[part 2 of 3: package /CAN4/Cluster]
AUTOSAR XML (schema 4-3-0)
package /CAN4/Cluster  (continued)
  can cluster CAN4: baudrate=500, can-fd-baudrate=2000  (continued)
    can physical channel CAN4: comm-connectors=ConnCAN4  (continued)
      frame CAN4_ZONE_DR_VCU: id 0x1F1, frame-length=48, can-addressing-mode=STANDARD, can-fd-frame-support=true, can-frame-rx-behavior=CAN-FD, can-frame-tx-behavior=CAN-FD
        pdu CAN4_ZONE_DR_VCU: length=48, minimum-delay=0.0, transmission-mode-true-timing={cyclic-timing=time-period=0.02, event-controlled-timing={number-of-repetitions=0, repetition-period=0}}, unused-bit-pattern=0
          mapping CAN4_SG_ZONE_DR_VCU: i-signal-group=CAN4_SG_ZONE_DR_VCU, start-position=0, transfer-property=TRIGGERED-ON-CHANGE
          signal CAN4_APTC_Err: start 215, 2 bit, big-endian, i-signal-type=PRIMITIVE, init-value=constant-reference=Init_CAN4_APTC_Err, base-type=uint8, implementation-data-type=uint8, transfer-property=TRIGGERED-ON-CHANGE
          signal CAN4_Blower_Err: start 213, 2 bit, big-endian, i-signal-type=PRIMITIVE, init-value=constant-reference=Init_CAN4_Blower_Err, base-type=uint8, implementation-data-type=uint8, transfer-property=TRIGGERED-ON-CHANGE
          signal CAN4_Blower_FB: start 71, 4 bit, big-endian, i-signal-type=PRIMITIVE, init-value=constant-reference=Init_CAN4_Blower_FB, base-type=uint8, implementation-data-type=uint8, transfer-property=PENDING
          signal CAN4_DrADASCurr: start 23, 8 bit, big-endian, i-signal-type=PRIMITIVE, init-value=constant-reference=Init_CAN4_DrADASCurr, base-type=uint8, implementation-data-type=uint8, transfer-property=PENDING
          signal CAN4_DrAPWLINErr: start 254, 1 bit, big-endian, i-signal-type=PRIMITIVE, init-value=constant-reference=Init_CAN4_DrAPWLINErr, base-type=uint8, implementation-data-type=uint8, transfer-property=TRIGGERED-ON-CHANGE
          signal CAN4_DrAPWStaErr: start 4, 1 bit, big-endian, i-signal-type=PRIMITIVE, init-value=constant-reference=Init_CAN4_DrAPWStaErr, base-type=uint8, implementation-data-type=uint8, transfer-property=TRIGGERED-ON-CHANGE
          signal CAN4_DrAuBoxPwrN1Curr: start 39, 8 bit, big-endian, i-signal-type=PRIMITIVE, init-value=constant-reference=Init_CAN4_DrAuBoxPwrN1Curr, base-type=uint8, implementation-data-type=uint8, transfer-property=PENDING
          signal CAN4_DrAuBoxPwrN2Curr: start 31, 8 bit, big-endian, i-signal-type=PRIMITIVE, init-value=constant-reference=Init_CAN4_DrAuBoxPwrN2Curr, base-type=uint8, implementation-data-type=uint8, transfer-property=PENDING
          signal CAN4_DrColumnSWFault: start 9, 2 bit, big-endian, i-signal-type=PRIMITIVE, init-value=constant-reference=Init_CAN4_DrColumnSWFault, base-type=uint8, implementation-data-type=uint8, transfer-property=PENDING
          signal CAN4_DrCtrlBDVolt: start 67, 12 bit, big-endian, i-signal-type=PRIMITIVE, init-value=constant-reference=Init_CAN4_DrCtrlBDVolt, base-type=uint16, implementation-data-type=uint16, transfer-property=PENDING
          signal CAN4_DrCtrlTemp: start 87, 16 bit, big-endian, i-signal-type=PRIMITIVE, init-value=constant-reference=Init_CAN4_DrCtrlTemp, base-type=uint16, implementation-data-type=uint16, transfer-property=PENDING
          signal CAN4_DrEOBDFault: start 1, 2 bit, big-endian, i-signal-type=PRIMITIVE, init-value=constant-reference=Init_CAN4_DrEOBDFault, base-type=uint8, implementation-data-type=uint8, transfer-property=PENDING
          signal CAN4_DrIVIFault: start 3, 2 bit, big-endian, i-signal-type=PRIMITIVE, init-value=constant-reference=Init_CAN4_DrIVIFault, base-type=uint8, implementation-data-type=uint8, transfer-property=PENDING
          signal CAN4_DrInfoErrSta: start 253, 1 bit, big-endian, i-signal-type=PRIMITIVE, init-value=constant-reference=Init_CAN4_DrInfoErrSta, base-type=uint8, implementation-data-type=uint8, transfer-property=TRIGGERED-ON-CHANGE
          signal CAN4_DrInfoFault: start 15, 2 bit, big-endian, i-signal-type=PRIMITIVE, init-value=constant-reference=Init_CAN4_DrInfoFault, base-type=uint8, implementation-data-type=uint8, transfer-property=PENDING
          signal CAN4_DrONA1ErrSta: start 252, 1 bit, big-endian, i-signal-type=PRIMITIVE, init-value=constant-reference=Init_CAN4_DrONA1ErrSta, base-type=uint8, implementation-data-type=uint8, transfer-property=TRIGGERED-ON-CHANGE
          signal CAN4_DrPMMLVOutPErrLmp: start 6, 1 bit, big-endian, i-signal-type=PRIMITIVE, init-value=constant-reference=Init_CAN4_DrPMMLVOutPErrLmp, base-type=uint8, implementation-data-type=uint8, transfer-property=TRIGGERED-ON-CHANGE
          signal CAN4_DrPMMLimpHomeActReq: start 5, 1 bit, big-endian, i-signal-type=PRIMITIVE, init-value=constant-reference=Init_CAN4_DrPMMLimpHomeActReq, base-type=uint8, implementation-data-type=uint8, transfer-property=TRIGGERED-ON-CHANGE
          signal CAN4_DrPMMSysErrLmp: start 7, 1 bit, big-endian, i-signal-type=PRIMITIVE, init-value=constant-reference=Init_CAN4_DrPMMSysErrLmp, base-type=uint8, implementation-data-type=uint8, transfer-property=TRIGGERED-ON-CHANGE
          signal CAN4_DrPowerTemp1: start 103, 16 bit, big-endian, i-signal-type=PRIMITIVE, init-value=constant-reference=Init_CAN4_DrPowerTemp1, base-type=uint16, implementation-data-type=uint16, transfer-property=PENDING
          signal CAN4_DrPowerTemp2: start 119, 16 bit, big-endian, i-signal-type=PRIMITIVE, init-value=constant-reference=Init_CAN4_DrPowerTemp2, base-type=uint16, implementation-data-type=uint16, transfer-property=PENDING
          signal CAN4_DrPwrInformationSta: start 261, 1 bit, big-endian, i-signal-type=PRIMITIVE, init-value=constant-reference=Init_CAN4_DrPwrInformationSta, base-type=uint8, implementation-data-type=uint8, transfer-property=TRIGGERED-ON-CHANGE
          signal CAN4_DrPwrONA1Curr: start 63, 8 bit, big-endian, i-signal-type=PRIMITIVE, init-value=constant-reference=Init_CAN4_DrPwrONA1Curr, base-type=uint8, implementation-data-type=uint8, transfer-property=PENDING
          signal CAN4_DrPwrONA2Curr: start 55, 8 bit, big-endian, i-signal-type=PRIMITIVE, init-value=constant-reference=Init_CAN4_DrPwrONA2Curr, base-type=uint8, implementation-data-type=uint8, transfer-property=PENDING
          signal CAN4_DrPwrSta: start 258, 3 bit, big-endian, i-signal-type=PRIMITIVE, init-value=constant-reference=Init_CAN4_DrPwrSta, base-type=uint8, implementation-data-type=uint8, transfer-property=TRIGGERED-ON-CHANGE
          signal CAN4_DrPwrStdbyACurr: start 47, 8 bit, big-endian, i-signal-type=PRIMITIVE, init-value=constant-reference=Init_CAN4_DrPwrStdbyACurr, base-type=uint8, implementation-data-type=uint8, transfer-property=PENDING
          signal CAN4_DrPwrWinErrSta: start 255, 1 bit, big-endian, i-signal-type=PRIMITIVE, init-value=constant-reference=Init_CAN4_DrPwrWinErrSta, base-type=uint8, implementation-data-type=uint8, transfer-property=TRIGGERED-ON-CHANGE
          signal CAN4_DrPwrWindowECUFault: start 13, 2 bit, big-endian, i-signal-type=PRIMITIVE, init-value=constant-reference=Init_CAN4_DrPwrWindowECUFault, base-type=uint8, implementation-data-type=uint8, transfer-property=PENDING
          signal CAN4_DrSCPSysErrLmp: start 260, 1 bit, big-endian, i-signal-type=PRIMITIVE, init-value=constant-reference=Init_CAN4_DrSCPSysErrLmp, base-type=uint8, implementation-data-type=uint8, transfer-property=TRIGGERED-ON-CHANGE
          signal CAN4_DrStdAErrSta: start 251, 1 bit, big-endian, i-signal-type=PRIMITIVE, init-value=constant-reference=Init_CAN4_DrStdAErrSta, base-type=uint8, implementation-data-type=uint8, transfer-property=TRIGGERED-ON-CHANGE
          signal CAN4_DrTHCMFault: start 11, 2 bit, big-endian, i-signal-type=PRIMITIVE, init-value=constant-reference=Init_CAN4_DrTHCMFault, base-type=uint8, implementation-data-type=uint8, transfer-property=PENDING
          signal CAN4_RegenSW_Err: start 262, 1 bit, big-endian, i-signal-type=PRIMITIVE, init-value=constant-reference=Init_CAN4_RegenSW_Err, base-type=uint8, implementation-data-type=uint8, transfer-property=TRIGGERED-ON-CHANGE
          signal CAN4_SolarL: start 207, 8 bit, big-endian, i-signal-type=PRIMITIVE, init-value=constant-reference=Init_CAN4_SolarL, base-type=uint8, implementation-data-type=uint8, transfer-property=PENDING
          signal CAN4_SolarL_Err: start 225, 2 bit, big-endian, i-signal-type=PRIMITIVE, init-value=constant-reference=Init_CAN4_SolarL_Err, base-type=uint8, implementation-data-type=uint8, transfer-property=TRIGGERED-ON-CHANGE
          signal CAN4_SolarR: start 199, 8 bit, big-endian, i-signal-type=PRIMITIVE, init-value=constant-reference=Init_CAN4_SolarR, base-type=uint8, implementation-data-type=uint8, transfer-property=PENDING
          signal CAN4_SolarR_Err: start 227, 2 bit, big-endian, i-signal-type=PRIMITIVE, init-value=constant-reference=Init_CAN4_SolarR_Err, base-type=uint8, implementation-data-type=uint8, transfer-property=TRIGGERED-ON-CHANGE
          signal CAN4_T_Face_L: start 175, 8 bit, big-endian, i-signal-type=PRIMITIVE, init-value=constant-reference=Init_CAN4_T_Face_L, base-type=uint8, implementation-data-type=uint8, transfer-property=PENDING
          signal CAN4_T_Face_L_Err: start 217, 2 bit, big-endian, i-signal-type=PRIMITIVE, init-value=constant-reference=Init_CAN4_T_Face_L_Err, base-type=uint8, implementation-data-type=uint8, transfer-property=TRIGGERED-ON-CHANGE
          signal CAN4_T_Face_R: start 167, 8 bit, big-endian, i-signal-type=PRIMITIVE, init-value=constant-reference=Init_CAN4_T_Face_R, base-type=uint8, implementation-data-type=uint8, transfer-property=PENDING
          signal CAN4_T_Face_R_Err: start 221, 2 bit, big-endian, i-signal-type=PRIMITIVE, init-value=constant-reference=Init_CAN4_T_Face_R_Err, base-type=uint8, implementation-data-type=uint8, transfer-property=TRIGGERED-ON-CHANGE
          signal CAN4_T_Face_Rr: start 151, 8 bit, big-endian, i-signal-type=PRIMITIVE, init-value=constant-reference=Init_CAN4_T_Face_Rr, base-type=uint8, implementation-data-type=uint8, transfer-property=PENDING
          signal CAN4_T_Face_Rr_Err: start 209, 2 bit, big-endian, i-signal-type=PRIMITIVE, init-value=constant-reference=Init_CAN4_T_Face_Rr_Err, base-type=uint8, implementation-data-type=uint8, transfer-property=TRIGGERED-ON-CHANGE
          signal CAN4_T_Foot_L: start 159, 8 bit, big-endian, i-signal-type=PRIMITIVE, init-value=constant-reference=Init_CAN4_T_Foot_L, base-type=uint8, implementation-data-type=uint8, transfer-property=PENDING
          signal CAN4_T_Foot_L_Err: start 219, 2 bit, big-endian, i-signal-type=PRIMITIVE, init-value=constant-reference=Init_CAN4_T_Foot_L_Err, base-type=uint8, implementation-data-type=uint8, transfer-property=TRIGGERED-ON-CHANGE
          signal CAN4_T_Foot_R: start 135, 8 bit, big-endian, i-signal-type=PRIMITIVE, init-value=constant-reference=Init_CAN4_T_Foot_R, base-type=uint8, implementation-data-type=uint8, transfer-property=PENDING
          signal CAN4_T_Foot_R_Err: start 223, 2 bit, big-endian, i-signal-type=PRIMITIVE, init-value=constant-reference=Init_CAN4_T_Foot_R_Err, base-type=uint8, implementation-data-type=uint8, transfer-property=TRIGGERED-ON-CHANGE
          signal CAN4_T_Foot_Rr: start 143, 8 bit, big-endian, i-signal-type=PRIMITIVE, init-value=constant-reference=Init_CAN4_T_Foot_Rr, base-type=uint8, implementation-data-type=uint8, transfer-property=PENDING
          signal CAN4_T_Foot_Rr_Err: start 211, 2 bit, big-endian, i-signal-type=PRIMITIVE, init-value=constant-reference=Init_CAN4_T_Foot_Rr_Err, base-type=uint8, implementation-data-type=uint8, transfer-property=TRIGGERED-ON-CHANGE
          signal CAN4_Tevap: start 183, 8 bit, big-endian, i-signal-type=PRIMITIVE, init-value=constant-reference=Init_CAN4_Tevap, base-type=uint8, implementation-data-type=uint8, transfer-property=PENDING
          signal CAN4_Tevap_Err: start 229, 2 bit, big-endian, i-signal-type=PRIMITIVE, init-value=constant-reference=Init_CAN4_Tevap_Err, base-type=uint8, implementation-data-type=uint8, transfer-property=TRIGGERED-ON-CHANGE
          signal CAN4_Tincar: start 191, 8 bit, big-endian, i-signal-type=PRIMITIVE, init-value=constant-reference=Init_CAN4_Tincar, base-type=uint8, implementation-data-type=uint8, transfer-property=PENDING
          signal CAN4_Tincar_Err: start 231, 2 bit, big-endian, i-signal-type=PRIMITIVE, init-value=constant-reference=Init_CAN4_Tincar_Err, base-type=uint8, implementation-data-type=uint8, transfer-property=TRIGGERED-ON-CHANGE
          signal CAN4_ZDR_SYS_APMRetryCnt_Sta: start 247, 8 bit, big-endian, i-signal-type=PRIMITIVE, init-value=constant-reference=Init_CAN4_ZDR_SYS_APMRetryCnt_Sta, base-type=uint8, implementation-data-type=uint8, transfer-property=TRIGGERED-ON-CHANGE
          signal CAN4_ZDR_SYS_BSWSleepReq_Sta: start 259, 1 bit, big-endian, i-signal-type=PRIMITIVE, init-value=constant-reference=Init_CAN4_ZDR_SYS_BSWSleepReq_Sta, base-type=uint8, implementation-data-type=uint8, transfer-property=TRIGGERED-ON-CHANGE
          signal CAN4_ZDR_SYS_CSWRetryCnt_Sta: start 239, 8 bit, big-endian, i-signal-type=PRIMITIVE, init-value=constant-reference=Init_CAN4_ZDR_SYS_CSWRetryCnt_Sta, base-type=uint8, implementation-data-type=uint8, transfer-property=TRIGGERED-ON-CHANGE
          signal CAN4_ZDR_VCU_HWReset_Sta: start 268, 5 bit, big-endian, i-signal-type=PRIMITIVE, init-value=constant-reference=Init_CAN4_ZDR_VCU_HWReset_Sta, base-type=uint8, implementation-data-type=uint8, transfer-property=TRIGGERED-ON-CHANGE
          signal CAN4_ZDR_VCU_PwrSupply_Sta: start 263, 1 bit, big-endian, i-signal-type=PRIMITIVE, init-value=constant-reference=Init_CAN4_ZDR_VCU_PwrSupply_Sta, base-type=uint8, implementation-data-type=uint8, transfer-property=TRIGGERED-ON-CHANGE
          signal CAN4_ZoneDrMalfunLevel: start 250, 3 bit, big-endian, i-signal-type=PRIMITIVE, init-value=constant-reference=Init_CAN4_ZoneDrMalfunLevel, base-type=uint8, implementation-data-type=uint8, transfer-property=TRIGGERED-ON-CHANGE
      frame CAN4_ZONE_FR1: id 0x31C, frame-length=64, can-addressing-mode=STANDARD, can-fd-frame-support=true, can-frame-rx-behavior=CAN-FD, can-frame-tx-behavior=CAN-FD
        pdu CAN4_ZONE_FR1: length=64, minimum-delay=0.0, transmission-mode-true-timing={cyclic-timing=time-period=0.1, event-controlled-timing={number-of-repetitions=0, repetition-period=0}}, unused-bit-pattern=0
          mapping CAN4_SG_ZONE_FR1: i-signal-group=CAN4_SG_ZONE_FR1, start-position=0, transfer-property=TRIGGERED-ON-CHANGE
          signal CAN4_AGS_Calibration_Enabled: start 191, 1 bit, big-endian, i-signal-type=PRIMITIVE, init-value=constant-reference=Init_CAN4_AGS_Calibration_Enabled, base-type=uint8, implementation-data-type=uint8, transfer-property=PENDING
          signal CAN4_AGS_Position_Request: start 183, 8 bit, big-endian, i-signal-type=PRIMITIVE, init-value=constant-reference=Init_CAN4_AGS_Position_Request, base-type=uint8, implementation-data-type=uint8, transfer-property=PENDING
          signal CAN4_BDC_1_MoveEnable: start 173, 1 bit, big-endian, i-signal-type=PRIMITIVE, init-value=constant-reference=Init_CAN4_BDC_1_MoveEnable, base-type=uint8, implementation-data-type=uint8, transfer-property=PENDING
          signal CAN4_BDC_1_ReqMovePos: start 143, 8 bit, big-endian, i-signal-type=PRIMITIVE, init-value=constant-reference=Init_CAN4_BDC_1_ReqMovePos, base-type=uint8, implementation-data-type=uint8, transfer-property=PENDING
          signal CAN4_BMSChksmHSC6: start 47, 8 bit, big-endian, i-signal-type=PRIMITIVE, init-value=constant-reference=Init_CAN4_BMSChksmHSC6, base-type=uint8, implementation-data-type=uint8, transfer-property=PENDING
          signal CAN4_BMSEnbPTCHSC6: start 69, 1 bit, big-endian, i-signal-type=PRIMITIVE, init-value=constant-reference=Init_CAN4_BMSEnbPTCHSC6, base-type=uint8, implementation-data-type=uint8, transfer-property=PENDING
          signal CAN4_BMSInptClntTemHSC6: start 24, 9 bit, big-endian, i-signal-type=PRIMITIVE, init-value=constant-reference=Init_CAN4_BMSInptClntTemHSC6, base-type=uint16, implementation-data-type=uint16, transfer-property=PENDING
          signal CAN4_BMSPackVol_h6HSC6: start 67, 12 bit, big-endian, i-signal-type=PRIMITIVE, init-value=constant-reference=Init_CAN4_BMSPackVol_h6HSC6, base-type=uint16, implementation-data-type=uint16, transfer-property=PENDING
          signal CAN4_BMSReqMdHSC6: start 71, 2 bit, big-endian, i-signal-type=PRIMITIVE, init-value=constant-reference=Init_CAN4_BMSReqMdHSC6, base-type=uint8, implementation-data-type=uint8, transfer-property=PENDING
          signal CAN4_BMSReqPWMHSC6: start 31, 7 bit, big-endian, i-signal-type=PRIMITIVE, init-value=constant-reference=Init_CAN4_BMSReqPWMHSC6, base-type=uint8, implementation-data-type=uint8, transfer-property=PENDING
          signal CAN4_BMSReqPwrHSC6: start 15, 16 bit, big-endian, i-signal-type=PRIMITIVE, init-value=constant-reference=Init_CAN4_BMSReqPwrHSC6, base-type=uint16, implementation-data-type=uint16, transfer-property=PENDING
          signal CAN4_BMSReqRlngCtrHSC6: start 7, 4 bit, big-endian, i-signal-type=PRIMITIVE, init-value=constant-reference=Init_CAN4_BMSReqRlngCtrHSC6, base-type=uint8, implementation-data-type=uint8, transfer-property=PENDING
          signal CAN4_BMSReqTapPosHSC6: start 3, 4 bit, big-endian, i-signal-type=PRIMITIVE, init-value=constant-reference=Init_CAN4_BMSReqTapPosHSC6, base-type=uint8, implementation-data-type=uint8, transfer-property=PENDING
          signal CAN4_CCM_SpdCmd: start 54, 15 bit, big-endian, i-signal-type=PRIMITIVE, init-value=constant-reference=Init_CAN4_CCM_SpdCmd, base-type=uint16, implementation-data-type=uint16, transfer-property=PENDING
          signal CAN4_CCV4_MoveEnable: start 168, 1 bit, big-endian, i-signal-type=PRIMITIVE, init-value=constant-reference=Init_CAN4_CCV4_MoveEnable, base-type=uint8, implementation-data-type=uint8, transfer-property=PENDING
          signal CAN4_CCV4_ReqMovePos: start 169, 1 bit, big-endian, i-signal-type=PRIMITIVE, init-value=constant-reference=Init_CAN4_CCV4_ReqMovePos, base-type=uint8, implementation-data-type=uint8, transfer-property=PENDING
          signal CAN4_ChargeInletLockSta: start 55, 1 bit, big-endian, i-signal-type=PRIMITIVE, init-value=constant-reference=Init_CAN4_ChargeInletLockSta, base-type=uint8, implementation-data-type=uint8, transfer-property=TRIGGERED-ON-CHANGE
          signal CAN4_CompProEN: start 68, 1 bit, big-endian, i-signal-type=PRIMITIVE, init-value=constant-reference=Init_CAN4_CompProEN, base-type=uint8, implementation-data-type=uint8, transfer-property=PENDING
          signal CAN4_EWP1_Default_Operation_EWP_Rq: start 170, 1 bit, big-endian, i-signal-type=PRIMITIVE, init-value=constant-reference=Init_CAN4_EWP1_Default_Operation_EWP_Rq, base-type=uint8, implementation-data-type=uint8, transfer-property=PENDING
          signal CAN4_EWP1_RPM_Target_EWP_Rq: start 119, 8 bit, big-endian, i-signal-type=PRIMITIVE, init-value=constant-reference=Init_CAN4_EWP1_RPM_Target_EWP_Rq, base-type=uint8, implementation-data-type=uint8, transfer-property=PENDING
          signal CAN4_EWP2_Default_Operation_EWP_Rq: start 171, 1 bit, big-endian, i-signal-type=PRIMITIVE, init-value=constant-reference=Init_CAN4_EWP2_Default_Operation_EWP_Rq, base-type=uint8, implementation-data-type=uint8, transfer-property=PENDING
          signal CAN4_EWP2_RPM_Target_EWP_Rq: start 127, 8 bit, big-endian, i-signal-type=PRIMITIVE, init-value=constant-reference=Init_CAN4_EWP2_RPM_Target_EWP_Rq, base-type=uint8, implementation-data-type=uint8, transfer-property=PENDING
          signal CAN4_EWP3_Default_Operation_EWP_Rq: start 172, 1 bit, big-endian, i-signal-type=PRIMITIVE, init-value=constant-reference=Init_CAN4_EWP3_Default_Operation_EWP_Rq, base-type=uint8, implementation-data-type=uint8, transfer-property=PENDING
          signal CAN4_EWP3_RPM_Target_EWP_Rq: start 135, 8 bit, big-endian, i-signal-type=PRIMITIVE, init-value=constant-reference=Init_CAN4_EWP3_RPM_Target_EWP_Rq, base-type=uint8, implementation-data-type=uint8, transfer-property=PENDING
          signal CAN4_EXV2_Cmd_Init_Rq: start 162, 3 bit, big-endian, i-signal-type=PRIMITIVE, init-value=constant-reference=Init_CAN4_EXV2_Cmd_Init_Rq, base-type=uint8, implementation-data-type=uint8, transfer-property=PENDING
          signal CAN4_EXV2_Cmd_Move_Enbl: start 167, 1 bit, big-endian, i-signal-type=PRIMITIVE, init-value=constant-reference=Init_CAN4_EXV2_Cmd_Move_Enbl, base-type=uint8, implementation-data-type=uint8, transfer-property=PENDING
          signal CAN4_EXV2_Cmd_Set_Rq: start 103, 16 bit, big-endian, i-signal-type=PRIMITIVE, init-value=constant-reference=Init_CAN4_EXV2_Cmd_Set_Rq, base-type=uint16, implementation-data-type=uint16, transfer-property=PENDING
          signal CAN4_EXV_Cmd_Init_Rq: start 165, 3 bit, big-endian, i-signal-type=PRIMITIVE, init-value=constant-reference=Init_CAN4_EXV_Cmd_Init_Rq, base-type=uint8, implementation-data-type=uint8, transfer-property=PENDING
          signal CAN4_EXV_Cmd_Move_Enbl: start 166, 1 bit, big-endian, i-signal-type=PRIMITIVE, init-value=constant-reference=Init_CAN4_EXV_Cmd_Move_Enbl, base-type=uint8, implementation-data-type=uint8, transfer-property=PENDING
          signal CAN4_EXV_Cmd_Set_Rq: start 87, 16 bit, big-endian, i-signal-type=PRIMITIVE, init-value=constant-reference=Init_CAN4_EXV_Cmd_Set_Rq, base-type=uint16, implementation-data-type=uint16, transfer-property=PENDING
          signal CAN4_FLPosLPErr: start 197, 1 bit, big-endian, i-signal-type=PRIMITIVE, init-value=constant-reference=Init_CAN4_FLPosLPErr, base-type=uint8, implementation-data-type=uint8, transfer-property=TRIGGERED-ON-CHANGE
          signal CAN4_FLTurnLPErr: start 198, 1 bit, big-endian, i-signal-type=PRIMITIVE, init-value=constant-reference=Init_CAN4_FLTurnLPErr, base-type=uint8, implementation-data-type=uint8, transfer-property=TRIGGERED-ON-CHANGE
          signal CAN4_FLTurnLampC: start 159, 8 bit, big-endian, i-signal-type=PRIMITIVE, init-value=constant-reference=Init_CAN4_FLTurnLampC, base-type=uint8, implementation-data-type=uint8, transfer-property=TRIGGERED-ON-CHANGE
          signal CAN4_FLTurn_Light_Warning: start 203, 1 bit, big-endian, i-signal-type=PRIMITIVE, init-value=constant-reference=Init_CAN4_FLTurn_Light_Warning, base-type=uint8, implementation-data-type=uint8, transfer-property=PENDING
          signal CAN4_FRPosLPErr: start 213, 1 bit, big-endian, i-signal-type=PRIMITIVE, init-value=constant-reference=Init_CAN4_FRPosLPErr, base-type=uint8, implementation-data-type=uint8, transfer-property=TRIGGERED-ON-CHANGE
          signal CAN4_FRTurnLPErr: start 214, 1 bit, big-endian, i-signal-type=PRIMITIVE, init-value=constant-reference=Init_CAN4_FRTurnLPErr, base-type=uint8, implementation-data-type=uint8, transfer-property=TRIGGERED-ON-CHANGE
          signal CAN4_FRTurnLampC: start 151, 8 bit, big-endian, i-signal-type=PRIMITIVE, init-value=constant-reference=Init_CAN4_FRTurnLampC, base-type=uint8, implementation-data-type=uint8, transfer-property=TRIGGERED-ON-CHANGE
          signal CAN4_FRTurn_Light_Warning: start 219, 1 bit, big-endian, i-signal-type=PRIMITIVE, init-value=constant-reference=Init_CAN4_FRTurn_Light_Warning, base-type=uint8, implementation-data-type=uint8, transfer-property=PENDING
          signal CAN4_FWiperAS: start 175, 1 bit, big-endian, i-signal-type=PRIMITIVE, init-value=constant-reference=Init_CAN4_FWiperAS, base-type=uint8, implementation-data-type=uint8, transfer-property=TRIGGERED-ON-CHANGE
          signal CAN4_FWiperProtection: start 174, 1 bit, big-endian, i-signal-type=PRIMITIVE, init-value=constant-reference=Init_CAN4_FWiperProtection, base-type=uint8, implementation-data-type=uint8, transfer-property=TRIGGERED-ON-CHANGE
          signal CAN4_LADBErr: start 194, 1 bit, big-endian, i-signal-type=PRIMITIVE, init-value=constant-reference=Init_CAN4_LADBErr, base-type=uint8, implementation-data-type=uint8, transfer-property=TRIGGERED-ON-CHANGE
          signal CAN4_LADB_Hibeam_Indication: start 192, 1 bit, big-endian, i-signal-type=PRIMITIVE, init-value=constant-reference=Init_CAN4_LADB_Hibeam_Indication, base-type=uint8, implementation-data-type=uint8, transfer-property=PENDING
          signal CAN4_LADB_Operation_Status: start 207, 1 bit, big-endian, i-signal-type=PRIMITIVE, init-value=constant-reference=Init_CAN4_LADB_Operation_Status, base-type=uint8, implementation-data-type=uint8, transfer-property=PENDING
          signal CAN4_LADB_Warning: start 206, 1 bit, big-endian, i-signal-type=PRIMITIVE, init-value=constant-reference=Init_CAN4_LADB_Warning, base-type=uint8, implementation-data-type=uint8, transfer-property=PENDING
          signal CAN4_LAHB_Warning: start 204, 1 bit, big-endian, i-signal-type=PRIMITIVE, init-value=constant-reference=Init_CAN4_LAHB_Warning, base-type=uint8, implementation-data-type=uint8, transfer-property=PENDING
          signal CAN4_LDRLErr: start 193, 1 bit, big-endian, i-signal-type=PRIMITIVE, init-value=constant-reference=Init_CAN4_LDRLErr, base-type=uint8, implementation-data-type=uint8, transfer-property=TRIGGERED-ON-CHANGE
          signal CAN4_LDRL_Warning: start 202, 1 bit, big-endian, i-signal-type=PRIMITIVE, init-value=constant-reference=Init_CAN4_LDRL_Warning, base-type=uint8, implementation-data-type=uint8, transfer-property=PENDING
          signal CAN4_LH_BeamErr: start 195, 1 bit, big-endian, i-signal-type=PRIMITIVE, init-value=constant-reference=Init_CAN4_LH_BeamErr, base-type=uint8, implementation-data-type=uint8, transfer-property=TRIGGERED-ON-CHANGE
          signal CAN4_LLB_Warning: start 205, 1 bit, big-endian, i-signal-type=PRIMITIVE, init-value=constant-reference=Init_CAN4_LLB_Warning, base-type=uint8, implementation-data-type=uint8, transfer-property=PENDING
          signal CAN4_LL_BeamErr: start 196, 1 bit, big-endian, i-signal-type=PRIMITIVE, init-value=constant-reference=Init_CAN4_LL_BeamErr, base-type=uint8, implementation-data-type=uint8, transfer-property=TRIGGERED-ON-CHANGE
          signal CAN4_Lposition_Lamp_Warning: start 199, 1 bit, big-endian, i-signal-type=PRIMITIVE, init-value=constant-reference=Init_CAN4_Lposition_Lamp_Warning, base-type=uint8, implementation-data-type=uint8, transfer-property=PENDING
          signal CAN4_RADBErr: start 210, 1 bit, big-endian, i-signal-type=PRIMITIVE, init-value=constant-reference=Init_CAN4_RADBErr, base-type=uint8, implementation-data-type=uint8, transfer-property=TRIGGERED-ON-CHANGE
          signal CAN4_RADB_Hibeam_Indication: start 208, 1 bit, big-endian, i-signal-type=PRIMITIVE, init-value=constant-reference=Init_CAN4_RADB_Hibeam_Indication, base-type=uint8, implementation-data-type=uint8, transfer-property=PENDING
          signal CAN4_RADB_Operation_Status: start 223, 1 bit, big-endian, i-signal-type=PRIMITIVE, init-value=constant-reference=Init_CAN4_RADB_Operation_Status, base-type=uint8, implementation-data-type=uint8, transfer-property=PENDING
          signal CAN4_RADB_Warning: start 222, 1 bit, big-endian, i-signal-type=PRIMITIVE, init-value=constant-reference=Init_CAN4_RADB_Warning, base-type=uint8, implementation-data-type=uint8, transfer-property=PENDING
          signal CAN4_RAHB_Warning: start 220, 1 bit, big-endian, i-signal-type=PRIMITIVE, init-value=constant-reference=Init_CAN4_RAHB_Warning, base-type=uint8, implementation-data-type=uint8, transfer-property=PENDING
          signal CAN4_RDRLErr: start 209, 1 bit, big-endian, i-signal-type=PRIMITIVE, init-value=constant-reference=Init_CAN4_RDRLErr, base-type=uint8, implementation-data-type=uint8, transfer-property=TRIGGERED-ON-CHANGE
          signal CAN4_RDRL_Warning: start 218, 1 bit, big-endian, i-signal-type=PRIMITIVE, init-value=constant-reference=Init_CAN4_RDRL_Warning, base-type=uint8, implementation-data-type=uint8, transfer-property=PENDING
          signal CAN4_RH_BeamErr: start 211, 1 bit, big-endian, i-signal-type=PRIMITIVE, init-value=constant-reference=Init_CAN4_RH_BeamErr, base-type=uint8, implementation-data-type=uint8, transfer-property=TRIGGERED-ON-CHANGE
          signal CAN4_RLB_Warning: start 221, 1 bit, big-endian, i-signal-type=PRIMITIVE, init-value=constant-reference=Init_CAN4_RLB_Warning, base-type=uint8, implementation-data-type=uint8, transfer-property=PENDING
          signal CAN4_RL_BeamErr: start 212, 1 bit, big-endian, i-signal-type=PRIMITIVE, init-value=constant-reference=Init_CAN4_RL_BeamErr, base-type=uint8, implementation-data-type=uint8, transfer-property=TRIGGERED-ON-CHANGE
          signal CAN4_Rposition_Lamp_Warning: start 215, 1 bit, big-endian, i-signal-type=PRIMITIVE, init-value=constant-reference=Init_CAN4_Rposition_Lamp_Warning, base-type=uint8, implementation-data-type=uint8, transfer-property=PENDING
          signal CAN4_TrailerCheck: start 190, 1 bit, big-endian, i-signal-type=PRIMITIVE, init-value=constant-reference=Init_CAN4_TrailerCheck, base-type=uint8, implementation-data-type=uint8, transfer-property=TRIGGERED-ON-CHANGE
          signal CAN4_TrailerModeSta: start 189, 2 bit, big-endian, i-signal-type=PRIMITIVE, init-value=constant-reference=Init_CAN4_TrailerModeSta, base-type=uint8, implementation-data-type=uint8, transfer-property=TRIGGERED-ON-CHANGE
          signal CAN4_ZFR_BCM_ChargerDoorSW_Sta: start 187, 1 bit, big-endian, i-signal-type=PRIMITIVE, init-value=constant-reference=Init_CAN4_ZFR_BCM_ChargerDoorSW_Sta, base-type=uint8, implementation-data-type=uint8, transfer-property=TRIGGERED-ON-CHANGE
          signal CAN4_ZFR_THCM_CLEVentActY_Sta: start 262, 7 bit, big-endian, i-signal-type=PRIMITIVE, init-value=constant-reference=Init_CAN4_ZFR_THCM_CLEVentActY_Sta, base-type=uint8, implementation-data-type=uint8, transfer-property=PENDING
          signal CAN4_ZFR_THCM_CLEVentActZ_Sta: start 270, 7 bit, big-endian, i-signal-type=PRIMITIVE, init-value=constant-reference=Init_CAN4_ZFR_THCM_CLEVentActZ_Sta, base-type=uint8, implementation-data-type=uint8, transfer-property=PENDING
          signal CAN4_ZFR_THCM_CREVentActY_Sta: start 278, 7 bit, big-endian, i-signal-type=PRIMITIVE, init-value=constant-reference=Init_CAN4_ZFR_THCM_CREVentActY_Sta, base-type=uint8, implementation-data-type=uint8, transfer-property=PENDING
          signal CAN4_ZFR_THCM_CREVentActZ_Sta: start 286, 7 bit, big-endian, i-signal-type=PRIMITIVE, init-value=constant-reference=Init_CAN4_ZFR_THCM_CREVentActZ_Sta, base-type=uint8, implementation-data-type=uint8, transfer-property=PENDING
          signal CAN4_ZFR_THCM_DrEVentActY_Sta: start 230, 7 bit, big-endian, i-signal-type=PRIMITIVE, init-value=constant-reference=Init_CAN4_ZFR_THCM_DrEVentActY_Sta, base-type=uint8, implementation-data-type=uint8, transfer-property=PENDING
          signal CAN4_ZFR_THCM_DrEVentActZ_Sta: start 238, 7 bit, big-endian, i-signal-type=PRIMITIVE, init-value=constant-reference=Init_CAN4_ZFR_THCM_DrEVentActZ_Sta, base-type=uint8, implementation-data-type=uint8, transfer-property=PENDING
          signal CAN4_ZFR_THCM_PsEVentActY_Sta: start 246, 7 bit, big-endian, i-signal-type=PRIMITIVE, init-value=constant-reference=Init_CAN4_ZFR_THCM_PsEVentActY_Sta, base-type=uint8, implementation-data-type=uint8, transfer-property=PENDING
          signal CAN4_ZFR_THCM_PsEVentActZ_Sta: start 254, 7 bit, big-endian, i-signal-type=PRIMITIVE, init-value=constant-reference=Init_CAN4_ZFR_THCM_PsEVentActZ_Sta, base-type=uint8, implementation-data-type=uint8, transfer-property=PENDING
      frame CAN4_ZONE_FR_VCU: id 0x1F2, frame-length=48, can-addressing-mode=STANDARD, can-fd-frame-support=true, can-frame-rx-behavior=CAN-FD, can-frame-tx-behavior=CAN-FD
        pdu CAN4_ZONE_FR_VCU: length=48, minimum-delay=0.0, transmission-mode-true-timing={cyclic-timing=time-period=0.02, event-controlled-timing={number-of-repetitions=0, repetition-period=0}}, unused-bit-pattern=0
          mapping CAN4_SG_ZONE_FR_VCU: i-signal-group=CAN4_SG_ZONE_FR_VCU, start-position=0, transfer-property=TRIGGERED-ON-CHANGE
          signal CAN4_AGS_Err: start 291, 2 bit, big-endian, i-signal-type=PRIMITIVE, init-value=constant-reference=Init_CAN4_AGS_Err, base-type=uint8, implementation-data-type=uint8, transfer-property=TRIGGERED-ON-CHANGE
          signal CAN4_Bat_In_Temp: start 263, 8 bit, big-endian, i-signal-type=PRIMITIVE, init-value=constant-reference=Init_CAN4_Bat_In_Temp, base-type=uint8, implementation-data-type=uint8, transfer-property=PENDING
          signal CAN4_Bat_In_Temp_Err: start 335, 2 bit, big-endian, i-signal-type=PRIMITIVE, init-value=constant-reference=Init_CAN4_Bat_In_Temp_Err, base-type=uint8, implementation-data-type=uint8, transfer-property=TRIGGERED-ON-CHANGE
          signal CAN4_Bat_Out_Temp: start 255, 8 bit, big-endian, i-signal-type=PRIMITIVE, init-value=constant-reference=Init_CAN4_Bat_Out_Temp, base-type=uint8, implementation-data-type=uint8, transfer-property=PENDING
          signal CAN4_Bat_Out_Temp_Err: start 323, 2 bit, big-endian, i-signal-type=PRIMITIVE, init-value=constant-reference=Init_CAN4_Bat_Out_Temp_Err, base-type=uint8, implementation-data-type=uint8, transfer-property=TRIGGERED-ON-CHANGE
          signal CAN4_COMP_Err: start 297, 2 bit, big-endian, i-signal-type=PRIMITIVE, init-value=constant-reference=Init_CAN4_COMP_Err, base-type=uint8, implementation-data-type=uint8, transfer-property=TRIGGERED-ON-CHANGE
          signal CAN4_EACProtectEnable: start 183, 2 bit, big-endian, i-signal-type=PRIMITIVE, init-value=constant-reference=Init_CAN4_EACProtectEnable, base-type=uint8, implementation-data-type=uint8, transfer-property=TRIGGERED-ON-CHANGE
          signal CAN4_EWP1_Err: start 295, 2 bit, big-endian, i-signal-type=PRIMITIVE, init-value=constant-reference=Init_CAN4_EWP1_Err, base-type=uint8, implementation-data-type=uint8, transfer-property=TRIGGERED-ON-CHANGE
          signal CAN4_EWP2_Err: start 283, 2 bit, big-endian, i-signal-type=PRIMITIVE, init-value=constant-reference=Init_CAN4_EWP2_Err, base-type=uint8, implementation-data-type=uint8, transfer-property=TRIGGERED-ON-CHANGE
          signal CAN4_EWP3_Err: start 285, 2 bit, big-endian, i-signal-type=PRIMITIVE, init-value=constant-reference=Init_CAN4_EWP3_Err, base-type=uint8, implementation-data-type=uint8, transfer-property=TRIGGERED-ON-CHANGE
          signal CAN4_EXV1_Err: start 301, 2 bit, big-endian, i-signal-type=PRIMITIVE, init-value=constant-reference=Init_CAN4_EXV1_Err, base-type=uint8, implementation-data-type=uint8, transfer-property=TRIGGERED-ON-CHANGE
          signal CAN4_EXV2_Err: start 303, 2 bit, big-endian, i-signal-type=PRIMITIVE, init-value=constant-reference=Init_CAN4_EXV2_Err, base-type=uint8, implementation-data-type=uint8, transfer-property=TRIGGERED-ON-CHANGE
          signal CAN4_FWV_Err: start 281, 2 bit, big-endian, i-signal-type=PRIMITIVE, init-value=constant-reference=Init_CAN4_FWV_Err, base-type=uint8, implementation-data-type=uint8, transfer-property=TRIGGERED-ON-CHANGE
          signal CAN4_Fan_Err: start 289, 2 bit, big-endian, i-signal-type=PRIMITIVE, init-value=constant-reference=Init_CAN4_Fan_Err, base-type=uint8, implementation-data-type=uint8, transfer-property=TRIGGERED-ON-CHANGE
          signal CAN4_FrBMSCCUCErr: start 84, 1 bit, big-endian, i-signal-type=PRIMITIVE, init-value=constant-reference=Init_CAN4_FrBMSCCUCErr, base-type=uint8, implementation-data-type=uint8, transfer-property=TRIGGERED-ON-CHANGE
          signal CAN4_FrBMS_CCU_CIRCurr: start 15, 8 bit, big-endian, i-signal-type=PRIMITIVE, init-value=constant-reference=Init_CAN4_FrBMS_CCU_CIRCurr, base-type=uint8, implementation-data-type=uint8, transfer-property=PENDING
          signal CAN4_FrBMS_CCU_CIRFault: start 39, 3 bit, big-endian, i-signal-type=PRIMITIVE, init-value=constant-reference=Init_CAN4_FrBMS_CCU_CIRFault, base-type=uint8, implementation-data-type=uint8, transfer-property=PENDING
          signal CAN4_FrCtrlBDVolt: start 107, 12 bit, big-endian, i-signal-type=PRIMITIVE, init-value=constant-reference=Init_CAN4_FrCtrlBDVolt, base-type=uint16, implementation-data-type=uint16, transfer-property=PENDING
          signal CAN4_FrCtrlTemp: start 127, 16 bit, big-endian, i-signal-type=PRIMITIVE, init-value=constant-reference=Init_CAN4_FrCtrlTemp, base-type=uint16, implementation-data-type=uint16, transfer-property=PENDING
          signal CAN4_FrEDUErr: start 83, 1 bit, big-endian, i-signal-type=PRIMITIVE, init-value=constant-reference=Init_CAN4_FrEDUErr, base-type=uint8, implementation-data-type=uint8, transfer-property=TRIGGERED-ON-CHANGE
          signal CAN4_FrEDU_INVERTERCurr: start 23, 8 bit, big-endian, i-signal-type=PRIMITIVE, init-value=constant-reference=Init_CAN4_FrEDU_INVERTERCurr, base-type=uint8, implementation-data-type=uint8, transfer-property=PENDING
          signal CAN4_FrEDU_INVERTERFault: start 36, 3 bit, big-endian, i-signal-type=PRIMITIVE, init-value=constant-reference=Init_CAN4_FrEDU_INVERTERFault, base-type=uint8, implementation-data-type=uint8, transfer-property=PENDING
          signal CAN4_FrIRC_1Curr: start 41, 10 bit, big-endian, i-signal-type=PRIMITIVE, init-value=constant-reference=Init_CAN4_FrIRC_1Curr, base-type=uint16, implementation-data-type=uint16, transfer-property=PENDING
          signal CAN4_FrIRC_2Curr: start 81, 10 bit, big-endian, i-signal-type=PRIMITIVE, init-value=constant-reference=Init_CAN4_FrIRC_2Curr, base-type=uint16, implementation-data-type=uint16, transfer-property=PENDING
          signal CAN4_FrPMMLVOutPErrLmp: start 46, 1 bit, big-endian, i-signal-type=PRIMITIVE, init-value=constant-reference=Init_CAN4_FrPMMLVOutPErrLmp, base-type=uint8, implementation-data-type=uint8, transfer-property=TRIGGERED-ON-CHANGE
          signal CAN4_FrPMMLimpHomeActReq: start 45, 1 bit, big-endian, i-signal-type=PRIMITIVE, init-value=constant-reference=Init_CAN4_FrPMMLimpHomeActReq, base-type=uint8, implementation-data-type=uint8, transfer-property=TRIGGERED-ON-CHANGE
          signal CAN4_FrPMMSysErrLmp: start 47, 1 bit, big-endian, i-signal-type=PRIMITIVE, init-value=constant-reference=Init_CAN4_FrPMMSysErrLmp, base-type=uint8, implementation-data-type=uint8, transfer-property=TRIGGERED-ON-CHANGE
          signal CAN4_FrPowerTemp1: start 159, 16 bit, big-endian, i-signal-type=PRIMITIVE, init-value=constant-reference=Init_CAN4_FrPowerTemp1, base-type=uint16, implementation-data-type=uint16, transfer-property=PENDING
          signal CAN4_FrPowerTemp2: start 143, 16 bit, big-endian, i-signal-type=PRIMITIVE, init-value=constant-reference=Init_CAN4_FrPowerTemp2, base-type=uint16, implementation-data-type=uint16, transfer-property=PENDING
          signal CAN4_FrPwrONA1Fault: start 25, 2 bit, big-endian, i-signal-type=PRIMITIVE, init-value=constant-reference=Init_CAN4_FrPwrONA1Fault, base-type=uint8, implementation-data-type=uint8, transfer-property=PENDING
          signal CAN4_FrPwrONA2Curr: start 79, 8 bit, big-endian, i-signal-type=PRIMITIVE, init-value=constant-reference=Init_CAN4_FrPwrONA2Curr, base-type=uint8, implementation-data-type=uint8, transfer-property=PENDING
          signal CAN4_FrPwrONA3Curr: start 71, 8 bit, big-endian, i-signal-type=PRIMITIVE, init-value=constant-reference=Init_CAN4_FrPwrONA3Curr, base-type=uint8, implementation-data-type=uint8, transfer-property=PENDING
          signal CAN4_FrPwrSta: start 111, 3 bit, big-endian, i-signal-type=PRIMITIVE, init-value=constant-reference=Init_CAN4_FrPwrSta, base-type=uint8, implementation-data-type=uint8, transfer-property=TRIGGERED-ON-CHANGE
          signal CAN4_FrPwrStdbyA1Fault: start 33, 2 bit, big-endian, i-signal-type=PRIMITIVE, init-value=constant-reference=Init_CAN4_FrPwrStdbyA1Fault, base-type=uint8, implementation-data-type=uint8, transfer-property=PENDING
          signal CAN4_FrPwrStdbyA1PlusCurr: start 103, 8 bit, big-endian, i-signal-type=PRIMITIVE, init-value=constant-reference=Init_CAN4_FrPwrStdbyA1PlusCurr, base-type=uint8, implementation-data-type=uint8, transfer-property=PENDING
          signal CAN4_FrPwrStdbyA1PlusFault: start 31, 3 bit, big-endian, i-signal-type=PRIMITIVE, init-value=constant-reference=Init_CAN4_FrPwrStdbyA1PlusFault, base-type=uint8, implementation-data-type=uint8, transfer-property=PENDING
          signal CAN4_FrPwrStdbyA2Curr: start 63, 8 bit, big-endian, i-signal-type=PRIMITIVE, init-value=constant-reference=Init_CAN4_FrPwrStdbyA2Curr, base-type=uint8, implementation-data-type=uint8, transfer-property=PENDING
          signal CAN4_FrPwrStdbyA2PlusCurr: start 7, 8 bit, big-endian, i-signal-type=PRIMITIVE, init-value=constant-reference=Init_CAN4_FrPwrStdbyA2PlusCurr, base-type=uint8, implementation-data-type=uint8, transfer-property=PENDING
          signal CAN4_FrPwrStdbyA2PlusFault: start 28, 3 bit, big-endian, i-signal-type=PRIMITIVE, init-value=constant-reference=Init_CAN4_FrPwrStdbyA2PlusFault, base-type=uint8, implementation-data-type=uint8, transfer-property=PENDING
          signal CAN4_FrStdA1PCErr: start 87, 1 bit, big-endian, i-signal-type=PRIMITIVE, init-value=constant-reference=Init_CAN4_FrStdA1PCErr, base-type=uint8, implementation-data-type=uint8, transfer-property=TRIGGERED-ON-CHANGE
          signal CAN4_FrStdA2PCErr: start 85, 1 bit, big-endian, i-signal-type=PRIMITIVE, init-value=constant-reference=Init_CAN4_FrStdA2PCErr, base-type=uint8, implementation-data-type=uint8, transfer-property=TRIGGERED-ON-CHANGE
          signal CAN4_FrStdA2PErr: start 86, 1 bit, big-endian, i-signal-type=PRIMITIVE, init-value=constant-reference=Init_CAN4_FrStdA2PErr, base-type=uint8, implementation-data-type=uint8, transfer-property=TRIGGERED-ON-CHANGE
          signal CAN4_Motor_In_Temp: start 279, 8 bit, big-endian, i-signal-type=PRIMITIVE, init-value=constant-reference=Init_CAN4_Motor_In_Temp, base-type=uint8, implementation-data-type=uint8, transfer-property=PENDING
          signal CAN4_Motor_In_Temp_Err: start 321, 2 bit, big-endian, i-signal-type=PRIMITIVE, init-value=constant-reference=Init_CAN4_Motor_In_Temp_Err, base-type=uint8, implementation-data-type=uint8, transfer-property=TRIGGERED-ON-CHANGE
          signal CAN4_Motor_Out_Temp: start 271, 8 bit, big-endian, i-signal-type=PRIMITIVE, init-value=constant-reference=Init_CAN4_Motor_Out_Temp, base-type=uint8, implementation-data-type=uint8, transfer-property=PENDING
          signal CAN4_Motor_Out_Temp_Err: start 325, 2 bit, big-endian, i-signal-type=PRIMITIVE, init-value=constant-reference=Init_CAN4_Motor_Out_Temp_Err, base-type=uint8, implementation-data-type=uint8, transfer-property=TRIGGERED-ON-CHANGE
          signal CAN4_PT_High_P: start 179, 12 bit, big-endian, i-signal-type=PRIMITIVE, init-value=constant-reference=Init_CAN4_PT_High_P, base-type=uint16, implementation-data-type=uint16, transfer-property=PENDING
          signal CAN4_PT_High_P_Err: start 319, 2 bit, big-endian, i-signal-type=PRIMITIVE, init-value=constant-reference=Init_CAN4_PT_High_P_Err, base-type=uint8, implementation-data-type=uint8, transfer-property=TRIGGERED-ON-CHANGE
          signal CAN4_PT_High_T: start 199, 8 bit, big-endian, i-signal-type=PRIMITIVE, init-value=constant-reference=Init_CAN4_PT_High_T, base-type=uint8, implementation-data-type=uint8, transfer-property=PENDING
          signal CAN4_PT_High_Tact: start 175, 8 bit, big-endian, i-signal-type=PRIMITIVE, init-value=constant-reference=Init_CAN4_PT_High_Tact, base-type=uint8, implementation-data-type=uint8, transfer-property=PENDING
          signal CAN4_PT_High_Tact_Err: start 305, 2 bit, big-endian, i-signal-type=PRIMITIVE, init-value=constant-reference=Init_CAN4_PT_High_Tact_Err, base-type=uint8, implementation-data-type=uint8, transfer-property=TRIGGERED-ON-CHANGE
          signal CAN4_PT_Low_P1: start 219, 12 bit, big-endian, i-signal-type=PRIMITIVE, init-value=constant-reference=Init_CAN4_PT_Low_P1, base-type=uint16, implementation-data-type=uint16, transfer-property=PENDING
          signal CAN4_PT_Low_P1_Err: start 327, 2 bit, big-endian, i-signal-type=PRIMITIVE, init-value=constant-reference=Init_CAN4_PT_Low_P1_Err, base-type=uint8, implementation-data-type=uint8, transfer-property=TRIGGERED-ON-CHANGE
          signal CAN4_PT_Low_P2: start 215, 12 bit, big-endian, i-signal-type=PRIMITIVE, init-value=constant-reference=Init_CAN4_PT_Low_P2, base-type=uint16, implementation-data-type=uint16, transfer-property=PENDING
          signal CAN4_PT_Low_P2_Err: start 315, 2 bit, big-endian, i-signal-type=PRIMITIVE, init-value=constant-reference=Init_CAN4_PT_Low_P2_Err, base-type=uint8, implementation-data-type=uint8, transfer-property=TRIGGERED-ON-CHANGE
          signal CAN4_PT_Low_T1: start 239, 8 bit, big-endian, i-signal-type=PRIMITIVE, init-value=constant-reference=Init_CAN4_PT_Low_T1, base-type=uint8, implementation-data-type=uint8, transfer-property=PENDING
          signal CAN4_PT_Low_T1_Err: start 313, 2 bit, big-endian, i-signal-type=PRIMITIVE, init-value=constant-reference=Init_CAN4_PT_Low_T1_Err, base-type=uint8, implementation-data-type=uint8, transfer-property=TRIGGERED-ON-CHANGE
          signal CAN4_PT_Low_T2: start 207, 8 bit, big-endian, i-signal-type=PRIMITIVE, init-value=constant-reference=Init_CAN4_PT_Low_T2, base-type=uint8, implementation-data-type=uint8, transfer-property=PENDING
          signal CAN4_PT_Low_T2_Err: start 317, 2 bit, big-endian, i-signal-type=PRIMITIVE, init-value=constant-reference=Init_CAN4_PT_Low_T2_Err, base-type=uint8, implementation-data-type=uint8, transfer-property=TRIGGERED-ON-CHANGE
          signal CAN4_SOTXV_Err: start 299, 2 bit, big-endian, i-signal-type=PRIMITIVE, init-value=constant-reference=Init_CAN4_SOTXV_Err, base-type=uint8, implementation-data-type=uint8, transfer-property=TRIGGERED-ON-CHANGE
          signal CAN4_SOV1_Err: start 307, 2 bit, big-endian, i-signal-type=PRIMITIVE, init-value=constant-reference=Init_CAN4_SOV1_Err, base-type=uint8, implementation-data-type=uint8, transfer-property=TRIGGERED-ON-CHANGE
          signal CAN4_SOV2_Err: start 309, 2 bit, big-endian, i-signal-type=PRIMITIVE, init-value=constant-reference=Init_CAN4_SOV2_Err, base-type=uint8, implementation-data-type=uint8, transfer-property=TRIGGERED-ON-CHANGE
          signal CAN4_SOV3_Err: start 311, 2 bit, big-endian, i-signal-type=PRIMITIVE, init-value=constant-reference=Init_CAN4_SOV3_Err, base-type=uint8, implementation-data-type=uint8, transfer-property=TRIGGERED-ON-CHANGE
          signal CAN4_TWV_Err: start 287, 2 bit, big-endian, i-signal-type=PRIMITIVE, init-value=constant-reference=Init_CAN4_TWV_Err, base-type=uint8, implementation-data-type=uint8, transfer-property=TRIGGERED-ON-CHANGE
          signal CAN4_Tamb: start 247, 8 bit, big-endian, i-signal-type=PRIMITIVE, init-value=constant-reference=Init_CAN4_Tamb, base-type=uint8, implementation-data-type=uint8, transfer-property=PENDING
          signal CAN4_Tamb_Err: start 333, 2 bit, big-endian, i-signal-type=PRIMITIVE, init-value=constant-reference=Init_CAN4_Tamb_Err, base-type=uint8, implementation-data-type=uint8, transfer-property=TRIGGERED-ON-CHANGE
          signal CAN4_WPTC_Err: start 293, 2 bit, big-endian, i-signal-type=PRIMITIVE, init-value=constant-reference=Init_CAN4_WPTC_Err, base-type=uint8, implementation-data-type=uint8, transfer-property=TRIGGERED-ON-CHANGE
          signal CAN4_ZFR_SYS_BMSCCURetryCnt_Sta: start 351, 8 bit, big-endian, i-signal-type=PRIMITIVE, init-value=constant-reference=Init_CAN4_ZFR_SYS_BMSCCURetryCnt_Sta, base-type=uint8, implementation-data-type=uint8, transfer-property=TRIGGERED-ON-CHANGE
          signal CAN4_ZFR_SYS_BSWSleepReq_Sta: start 82, 1 bit, big-endian, i-signal-type=PRIMITIVE, init-value=constant-reference=Init_CAN4_ZFR_SYS_BSWSleepReq_Sta, base-type=uint8, implementation-data-type=uint8, transfer-property=TRIGGERED-ON-CHANGE
          signal CAN4_ZFR_SYS_MCURetryCnt_Sta: start 343, 8 bit, big-endian, i-signal-type=PRIMITIVE, init-value=constant-reference=Init_CAN4_ZFR_SYS_MCURetryCnt_Sta, base-type=uint8, implementation-data-type=uint8, transfer-property=TRIGGERED-ON-CHANGE
          signal CAN4_ZFR_VCU_HWReset_Sta: start 356, 5 bit, big-endian, i-signal-type=PRIMITIVE, init-value=constant-reference=Init_CAN4_ZFR_VCU_HWReset_Sta, base-type=uint8, implementation-data-type=uint8, transfer-property=TRIGGERED-ON-CHANGE
          signal CAN4_ZFR_VCU_PwrSupply_Sta: start 108, 1 bit, big-endian, i-signal-type=PRIMITIVE, init-value=constant-reference=Init_CAN4_ZFR_VCU_PwrSupply_Sta, base-type=uint8, implementation-data-type=uint8, transfer-property=TRIGGERED-ON-CHANGE
          signal CAN4_ZoneFrMalfunLevel: start 44, 3 bit, big-endian, i-signal-type=PRIMITIVE, init-value=constant-reference=Init_CAN4_ZoneFrMalfunLevel, base-type=uint8, implementation-data-type=uint8, transfer-property=TRIGGERED-ON-CHANGE
      frame CAN4_ZONE_L1: id 0x35A, frame-length=12, can-addressing-mode=STANDARD, can-fd-frame-support=true, can-frame-rx-behavior=CAN-FD, can-frame-tx-behavior=CAN-FD
        pdu CAN4_ZONE_L1: length=12, minimum-delay=0.0, transmission-mode-true-timing={cyclic-timing=time-period=0.2, event-controlled-timing={number-of-repetitions=0, repetition-period=0}}, unused-bit-pattern=0
          mapping CAN4_SG_ZONE_L1: i-signal-group=CAN4_SG_ZONE_L1, start-position=0, transfer-property=TRIGGERED-ON-CHANGE
          signal CAN4_ZL_DSEAT_AntiAct_Sta: start 45, 1 bit, big-endian, i-signal-type=PRIMITIVE, init-value=constant-reference=Init_CAN4_ZL_DSEAT_AntiAct_Sta, base-type=uint8, implementation-data-type=uint8, transfer-property=TRIGGERED-ON-CHANGE
          signal CAN4_ZL_DSEAT_Anti_Sta: start 43, 1 bit, big-endian, i-signal-type=PRIMITIVE, init-value=constant-reference=Init_CAN4_ZL_DSEAT_Anti_Sta, base-type=uint8, implementation-data-type=uint8, transfer-property=TRIGGERED-ON-CHANGE
          signal CAN4_ZL_DSEAT_EntryAct_Sta: start 39, 1 bit, big-endian, i-signal-type=PRIMITIVE, init-value=constant-reference=Init_CAN4_ZL_DSEAT_EntryAct_Sta, base-type=uint8, implementation-data-type=uint8, transfer-property=TRIGGERED-ON-CHANGE
          signal CAN4_ZL_DSEAT_EntryFun_Sta: start 44, 1 bit, big-endian, i-signal-type=PRIMITIVE, init-value=constant-reference=Init_CAN4_ZL_DSEAT_EntryFun_Sta, base-type=uint8, implementation-data-type=uint8, transfer-property=TRIGGERED-ON-CHANGE
          signal CAN4_ZL_DSEAT_Error_Sta: start 35, 1 bit, big-endian, i-signal-type=PRIMITIVE, init-value=constant-reference=Init_CAN4_ZL_DSEAT_Error_Sta, base-type=uint8, implementation-data-type=uint8, transfer-property=TRIGGERED-ON-CHANGE
          signal CAN4_ZL_DSEAT_FLPos_Sta: start 7, 8 bit, big-endian, i-signal-type=PRIMITIVE, init-value=constant-reference=Init_CAN4_ZL_DSEAT_FLPos_Sta, base-type=uint8, implementation-data-type=uint8, transfer-property=PENDING
          signal CAN4_ZL_DSEAT_MemSet_Sta: start 47, 2 bit, big-endian, i-signal-type=PRIMITIVE, init-value=constant-reference=Init_CAN4_ZL_DSEAT_MemSet_Sta, base-type=uint8, implementation-data-type=uint8, transfer-property=TRIGGERED-ON-CHANGE
          signal CAN4_ZL_DSEAT_Mode_Sta: start 38, 3 bit, big-endian, i-signal-type=PRIMITIVE, init-value=constant-reference=Init_CAN4_ZL_DSEAT_Mode_Sta, base-type=uint8, implementation-data-type=uint8, transfer-property=TRIGGERED-ON-CHANGE
          signal CAN4_ZL_DSEAT_RLPos_Sta: start 23, 8 bit, big-endian, i-signal-type=PRIMITIVE, init-value=constant-reference=Init_CAN4_ZL_DSEAT_RLPos_Sta, base-type=uint8, implementation-data-type=uint8, transfer-property=PENDING
          signal CAN4_ZL_DSEAT_RecPos_Sta: start 31, 8 bit, big-endian, i-signal-type=PRIMITIVE, init-value=constant-reference=Init_CAN4_ZL_DSEAT_RecPos_Sta, base-type=uint8, implementation-data-type=uint8, transfer-property=PENDING
          signal CAN4_ZL_DSEAT_SlidPos_Sta: start 15, 8 bit, big-endian, i-signal-type=PRIMITIVE, init-value=constant-reference=Init_CAN4_ZL_DSEAT_SlidPos_Sta, base-type=uint8, implementation-data-type=uint8, transfer-property=PENDING
          signal CAN4_ZL_DSEAT_Vent_Sta: start 34, 3 bit, big-endian, i-signal-type=PRIMITIVE, init-value=constant-reference=Init_CAN4_ZL_DSEAT_Vent_Sta, base-type=uint8, implementation-data-type=uint8, transfer-property=TRIGGERED-ON-CHANGE
          signal CAN4_ZL_DSEAT_heater_Sta: start 42, 3 bit, big-endian, i-signal-type=PRIMITIVE, init-value=constant-reference=Init_CAN4_ZL_DSEAT_heater_Sta, base-type=uint8, implementation-data-type=uint8, transfer-property=TRIGGERED-ON-CHANGE
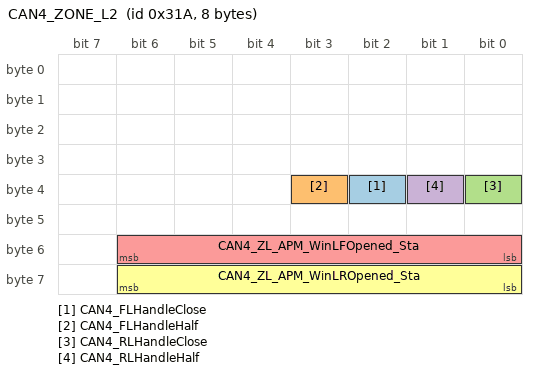
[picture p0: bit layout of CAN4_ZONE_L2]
      frame CAN4_ZONE_L2: id 0x31A, frame-length=8, can-addressing-mode=STANDARD, can-fd-frame-support=true, can-frame-rx-behavior=CAN-FD, can-frame-tx-behavior=CAN-FD
        pdu CAN4_ZONE_L2: length=8, minimum-delay=0.0, transmission-mode-true-timing={cyclic-timing=time-period=0.1, event-controlled-timing={number-of-repetitions=0, repetition-period=0}}, unused-bit-pattern=0
          mapping CAN4_SG_ZONE_L2: i-signal-group=CAN4_SG_ZONE_L2, start-position=0, transfer-property=TRIGGERED-ON-CHANGE
          signal CAN4_FLHandleClose: start 34, 1 bit, big-endian, i-signal-type=PRIMITIVE, init-value=constant-reference=Init_CAN4_FLHandleClose, base-type=uint8, implementation-data-type=uint8, transfer-property=TRIGGERED-ON-CHANGE
          signal CAN4_FLHandleHalf: start 35, 1 bit, big-endian, i-signal-type=PRIMITIVE, init-value=constant-reference=Init_CAN4_FLHandleHalf, base-type=uint8, implementation-data-type=uint8, transfer-property=TRIGGERED-ON-CHANGE
          signal CAN4_RLHandleClose: start 32, 1 bit, big-endian, i-signal-type=PRIMITIVE, init-value=constant-reference=Init_CAN4_RLHandleClose, base-type=uint8, implementation-data-type=uint8, transfer-property=TRIGGERED-ON-CHANGE
          signal CAN4_RLHandleHalf: start 33, 1 bit, big-endian, i-signal-type=PRIMITIVE, init-value=constant-reference=Init_CAN4_RLHandleHalf, base-type=uint8, implementation-data-type=uint8, transfer-property=TRIGGERED-ON-CHANGE
          signal CAN4_ZL_APM_WinLFOpened_Sta: start 54, 7 bit, big-endian, i-signal-type=PRIMITIVE, init-value=constant-reference=Init_CAN4_ZL_APM_WinLFOpened_Sta, base-type=uint8, implementation-data-type=uint8, transfer-property=PENDING
          signal CAN4_ZL_APM_WinLROpened_Sta: start 62, 7 bit, big-endian, i-signal-type=PRIMITIVE, init-value=constant-reference=Init_CAN4_ZL_APM_WinLROpened_Sta, base-type=uint8, implementation-data-type=uint8, transfer-property=PENDING
      frame CAN4_ZONE_R1: id 0x35B, frame-length=32, can-addressing-mode=STANDARD, can-fd-frame-support=true, can-frame-rx-behavior=CAN-FD, can-frame-tx-behavior=CAN-FD
        pdu CAN4_ZONE_R1: length=32, minimum-delay=0.0, transmission-mode-true-timing={cyclic-timing=time-period=0.1, event-controlled-timing={number-of-repetitions=0, repetition-period=0}}, unused-bit-pattern=0
          mapping CAN4_SG_ZONE_R1: i-signal-group=CAN4_SG_ZONE_R1, start-position=0, transfer-property=TRIGGERED-ON-CHANGE
          signal CAN4_ZR_PSEAT_Error_Sta: start 179, 1 bit, big-endian, i-signal-type=PRIMITIVE, init-value=constant-reference=Init_CAN4_ZR_PSEAT_Error_Sta, base-type=uint8, implementation-data-type=uint8, transfer-property=TRIGGERED-ON-CHANGE
          signal CAN4_ZR_PSEAT_Mode_Sta: start 178, 3 bit, big-endian, i-signal-type=PRIMITIVE, init-value=constant-reference=Init_CAN4_ZR_PSEAT_Mode_Sta, base-type=uint8, implementation-data-type=uint8, transfer-property=TRIGGERED-ON-CHANGE
          signal CAN4_ZR_PSEAT_Vent_Sta: start 182, 3 bit, big-endian, i-signal-type=PRIMITIVE, init-value=constant-reference=Init_CAN4_ZR_PSEAT_Vent_Sta, base-type=uint8, implementation-data-type=uint8, transfer-property=TRIGGERED-ON-CHANGE
          signal CAN4_ZR_PSEAT_heater_Sta: start 186, 3 bit, big-endian, i-signal-type=PRIMITIVE, init-value=constant-reference=Init_CAN4_ZR_PSEAT_heater_Sta, base-type=uint8, implementation-data-type=uint8, transfer-property=TRIGGERED-ON-CHANGE
          signal CAN4_ZR_PTG_AbuseProtection_Sta: start 111, 1 bit, big-endian, i-signal-type=PRIMITIVE, init-value=constant-reference=Init_CAN4_ZR_PTG_AbuseProtection_Sta, base-type=uint8, implementation-data-type=uint8, transfer-property=TRIGGERED-ON-CHANGE
          signal CAN4_ZR_PTG_Active_Sta: start 28, 3 bit, big-endian, i-signal-type=PRIMITIVE, init-value=constant-reference=Init_CAN4_ZR_PTG_Active_Sta, base-type=uint8, implementation-data-type=uint8, transfer-property=TRIGGERED-ON-CHANGE
          signal CAN4_ZR_PTG_CinchCur_Sta: start 110, 15 bit, big-endian, i-signal-type=PRIMITIVE, init-value=constant-reference=Init_CAN4_ZR_PTG_CinchCur_Sta, base-type=uint16, implementation-data-type=uint16, transfer-property=PENDING
          signal CAN4_ZR_PTG_CinchDuty_Sta: start 70, 7 bit, big-endian, i-signal-type=PRIMITIVE, init-value=constant-reference=Init_CAN4_ZR_PTG_CinchDuty_Sta, base-type=uint8, implementation-data-type=uint8, transfer-property=PENDING
          signal CAN4_ZR_PTG_DebugMode_Sta: start 31, 1 bit, big-endian, i-signal-type=PRIMITIVE, init-value=constant-reference=Init_CAN4_ZR_PTG_DebugMode_Sta, base-type=uint8, implementation-data-type=uint8, transfer-property=TRIGGERED-ON-CHANGE
          signal CAN4_ZR_PTG_ErrHall_Sta: start 157, 2 bit, big-endian, i-signal-type=PRIMITIVE, init-value=constant-reference=Init_CAN4_ZR_PTG_ErrHall_Sta, base-type=uint8, implementation-data-type=uint8, transfer-property=TRIGGERED-ON-CHANGE
          signal CAN4_ZR_PTG_ErrLatch_Sta: start 159, 2 bit, big-endian, i-signal-type=PRIMITIVE, init-value=constant-reference=Init_CAN4_ZR_PTG_ErrLatch_Sta, base-type=uint8, implementation-data-type=uint8, transfer-property=TRIGGERED-ON-CHANGE
          signal CAN4_ZR_PTG_ErrLeftStrut_Sta: start 139, 2 bit, big-endian, i-signal-type=PRIMITIVE, init-value=constant-reference=Init_CAN4_ZR_PTG_ErrLeftStrut_Sta, base-type=uint8, implementation-data-type=uint8, transfer-property=TRIGGERED-ON-CHANGE
          signal CAN4_ZR_PTG_ErrRightStrut_Sta: start 143, 2 bit, big-endian, i-signal-type=PRIMITIVE, init-value=constant-reference=Init_CAN4_ZR_PTG_ErrRightStrut_Sta, base-type=uint8, implementation-data-type=uint8, transfer-property=TRIGGERED-ON-CHANGE
          signal CAN4_ZR_PTG_ErrVoltage_Sta: start 141, 2 bit, big-endian, i-signal-type=PRIMITIVE, init-value=constant-reference=Init_CAN4_ZR_PTG_ErrVoltage_Sta, base-type=uint8, implementation-data-type=uint8, transfer-property=TRIGGERED-ON-CHANGE
          signal CAN4_ZR_PTG_Exist_Sta: start 25, 1 bit, big-endian, i-signal-type=PRIMITIVE, init-value=constant-reference=Init_CAN4_ZR_PTG_Exist_Sta, base-type=uint8, implementation-data-type=uint8, transfer-property=TRIGGERED-ON-CHANGE
          signal CAN4_ZR_PTG_FullSW_Sta: start 55, 1 bit, big-endian, i-signal-type=PRIMITIVE, init-value=constant-reference=Init_CAN4_ZR_PTG_FullSW_Sta, base-type=uint8, implementation-data-type=uint8, transfer-property=TRIGGERED-ON-CHANGE
          signal CAN4_ZR_PTG_HalfSW_Sta: start 47, 1 bit, big-endian, i-signal-type=PRIMITIVE, init-value=constant-reference=Init_CAN4_ZR_PTG_HalfSW_Sta, base-type=uint8, implementation-data-type=uint8, transfer-property=TRIGGERED-ON-CHANGE
          signal CAN4_ZR_PTG_InsideSW1_Sta: start 37, 2 bit, big-endian, i-signal-type=PRIMITIVE, init-value=constant-reference=Init_CAN4_ZR_PTG_InsideSW1_Sta, base-type=uint8, implementation-data-type=uint8, transfer-property=TRIGGERED-ON-CHANGE
          signal CAN4_ZR_PTG_InsideSW2_Sta: start 35, 2 bit, big-endian, i-signal-type=PRIMITIVE, init-value=constant-reference=Init_CAN4_ZR_PTG_InsideSW2_Sta, base-type=uint8, implementation-data-type=uint8, transfer-property=TRIGGERED-ON-CHANGE
          signal CAN4_ZR_PTG_IsSetHeight_Sta: start 24, 1 bit, big-endian, i-signal-type=PRIMITIVE, init-value=constant-reference=Init_CAN4_ZR_PTG_IsSetHeight_Sta, base-type=uint8, implementation-data-type=uint8, transfer-property=TRIGGERED-ON-CHANGE
          signal CAN4_ZR_PTG_LatchSeg_Sta: start 33, 2 bit, big-endian, i-signal-type=PRIMITIVE, init-value=constant-reference=Init_CAN4_ZR_PTG_LatchSeg_Sta, base-type=uint8, implementation-data-type=uint8, transfer-property=TRIGGERED-ON-CHANGE
          signal CAN4_ZR_PTG_LatchThermal_Sta: start 127, 1 bit, big-endian, i-signal-type=PRIMITIVE, init-value=constant-reference=Init_CAN4_ZR_PTG_LatchThermal_Sta, base-type=uint8, implementation-data-type=uint8, transfer-property=TRIGGERED-ON-CHANGE
          signal CAN4_ZR_PTG_LeftCur_Sta: start 78, 15 bit, big-endian, i-signal-type=PRIMITIVE, init-value=constant-reference=Init_CAN4_ZR_PTG_LeftCur_Sta, base-type=uint16, implementation-data-type=uint16, transfer-property=PENDING
          signal CAN4_ZR_PTG_LeftDuty_Sta: start 54, 7 bit, big-endian, i-signal-type=PRIMITIVE, init-value=constant-reference=Init_CAN4_ZR_PTG_LeftDuty_Sta, base-type=uint8, implementation-data-type=uint8, transfer-property=PENDING
          signal CAN4_ZR_PTG_LeftHallPosn_Sta: start 137, 10 bit, big-endian, i-signal-type=PRIMITIVE, init-value=constant-reference=Init_CAN4_ZR_PTG_LeftHallPosn_Sta, base-type=uint16, implementation-data-type=uint16, transfer-property=PENDING
          signal CAN4_ZR_PTG_NtlSW_Sta: start 63, 1 bit, big-endian, i-signal-type=PRIMITIVE, init-value=constant-reference=Init_CAN4_ZR_PTG_NtlSW_Sta, base-type=uint8, implementation-data-type=uint8, transfer-property=TRIGGERED-ON-CHANGE
          signal CAN4_ZR_PTG_OpenRatio_Sta: start 46, 7 bit, big-endian, i-signal-type=PRIMITIVE, init-value=constant-reference=Init_CAN4_ZR_PTG_OpenRatio_Sta, base-type=uint8, implementation-data-type=uint8, transfer-property=PENDING
          signal CAN4_ZR_PTG_PowerLatch_Sta: start 23, 3 bit, big-endian, i-signal-type=PRIMITIVE, init-value=constant-reference=Init_CAN4_ZR_PTG_PowerLatch_Sta, base-type=uint8, implementation-data-type=uint8, transfer-property=TRIGGERED-ON-CHANGE
          signal CAN4_ZR_PTG_RDIL_Cmd: start 39, 2 bit, big-endian, i-signal-type=PRIMITIVE, init-value=constant-reference=Init_CAN4_ZR_PTG_RDIL_Cmd, base-type=uint8, implementation-data-type=uint8, transfer-property=TRIGGERED-ON-CHANGE
          signal CAN4_ZR_PTG_ReleaseCur_Sta: start 126, 15 bit, big-endian, i-signal-type=PRIMITIVE, init-value=constant-reference=Init_CAN4_ZR_PTG_ReleaseCur_Sta, base-type=uint16, implementation-data-type=uint16, transfer-property=PENDING
          signal CAN4_ZR_PTG_RightCur_Sta: start 94, 15 bit, big-endian, i-signal-type=PRIMITIVE, init-value=constant-reference=Init_CAN4_ZR_PTG_RightCur_Sta, base-type=uint16, implementation-data-type=uint16, transfer-property=PENDING
          signal CAN4_ZR_PTG_RightDuty_Sta: start 62, 7 bit, big-endian, i-signal-type=PRIMITIVE, init-value=constant-reference=Init_CAN4_ZR_PTG_RightDuty_Sta, base-type=uint8, implementation-data-type=uint8, transfer-property=PENDING
          signal CAN4_ZR_PTG_RightHallPosn_Sta: start 153, 10 bit, big-endian, i-signal-type=PRIMITIVE, init-value=constant-reference=Init_CAN4_ZR_PTG_RightHallPosn_Sta, base-type=uint16, implementation-data-type=uint16, transfer-property=PENDING
          signal CAN4_ZR_PTG_StrutAntiPinch_Sta: start 79, 1 bit, big-endian, i-signal-type=PRIMITIVE, init-value=constant-reference=Init_CAN4_ZR_PTG_StrutAntiPinch_Sta, base-type=uint8, implementation-data-type=uint8, transfer-property=TRIGGERED-ON-CHANGE
          signal CAN4_ZR_PTG_StrutStall_Sta: start 95, 1 bit, big-endian, i-signal-type=PRIMITIVE, init-value=constant-reference=Init_CAN4_ZR_PTG_StrutStall_Sta, base-type=uint8, implementation-data-type=uint8, transfer-property=TRIGGERED-ON-CHANGE
          signal CAN4_ZR_PTG_StrutThermal_Sta: start 71, 1 bit, big-endian, i-signal-type=PRIMITIVE, init-value=constant-reference=Init_CAN4_ZR_PTG_StrutThermal_Sta, base-type=uint8, implementation-data-type=uint8, transfer-property=TRIGGERED-ON-CHANGE
          signal CAN4_ZR_PTG_Sys_Sta: start 30, 2 bit, big-endian, i-signal-type=PRIMITIVE, init-value=constant-reference=Init_CAN4_ZR_PTG_Sys_Sta, base-type=uint8, implementation-data-type=uint8, transfer-property=TRIGGERED-ON-CHANGE
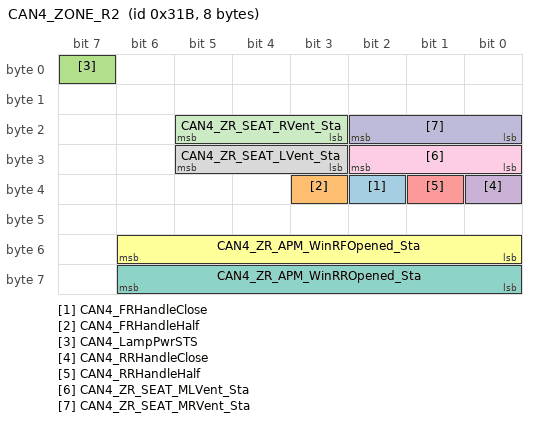
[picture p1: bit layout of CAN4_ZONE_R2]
      frame CAN4_ZONE_R2: id 0x31B, frame-length=8, can-addressing-mode=STANDARD, can-fd-frame-support=true, can-frame-rx-behavior=CAN-FD, can-frame-tx-behavior=CAN-FD
        pdu CAN4_ZONE_R2: length=8, minimum-delay=0.0, transmission-mode-true-timing={cyclic-timing=time-period=0.1, event-controlled-timing={number-of-repetitions=0, repetition-period=0}}, unused-bit-pattern=0
          mapping CAN4_SG_ZONE_R2: i-signal-group=CAN4_SG_ZONE_R2, start-position=0, transfer-property=TRIGGERED-ON-CHANGE
          signal CAN4_FRHandleClose: start 34, 1 bit, big-endian, i-signal-type=PRIMITIVE, init-value=constant-reference=Init_CAN4_FRHandleClose, base-type=uint8, implementation-data-type=uint8, transfer-property=TRIGGERED-ON-CHANGE
          signal CAN4_FRHandleHalf: start 35, 1 bit, big-endian, i-signal-type=PRIMITIVE, init-value=constant-reference=Init_CAN4_FRHandleHalf, base-type=uint8, implementation-data-type=uint8, transfer-property=TRIGGERED-ON-CHANGE
          signal CAN4_LampPwrSTS: start 7, 1 bit, big-endian, i-signal-type=PRIMITIVE, init-value=constant-reference=Init_CAN4_LampPwrSTS, base-type=uint8, implementation-data-type=uint8, transfer-property=TRIGGERED-ON-CHANGE
          signal CAN4_RRHandleClose: start 32, 1 bit, big-endian, i-signal-type=PRIMITIVE, init-value=constant-reference=Init_CAN4_RRHandleClose, base-type=uint8, implementation-data-type=uint8, transfer-property=TRIGGERED-ON-CHANGE
          signal CAN4_RRHandleHalf: start 33, 1 bit, big-endian, i-signal-type=PRIMITIVE, init-value=constant-reference=Init_CAN4_RRHandleHalf, base-type=uint8, implementation-data-type=uint8, transfer-property=TRIGGERED-ON-CHANGE
          signal CAN4_ZR_APM_WinRFOpened_Sta: start 54, 7 bit, big-endian, i-signal-type=PRIMITIVE, init-value=constant-reference=Init_CAN4_ZR_APM_WinRFOpened_Sta, base-type=uint8, implementation-data-type=uint8, transfer-property=PENDING
          signal CAN4_ZR_APM_WinRROpened_Sta: start 62, 7 bit, big-endian, i-signal-type=PRIMITIVE, init-value=constant-reference=Init_CAN4_ZR_APM_WinRROpened_Sta, base-type=uint8, implementation-data-type=uint8, transfer-property=PENDING
          signal CAN4_ZR_SEAT_LVent_Sta: start 29, 3 bit, big-endian, i-signal-type=PRIMITIVE, init-value=constant-reference=Init_CAN4_ZR_SEAT_LVent_Sta, base-type=uint8, implementation-data-type=uint8, transfer-property=TRIGGERED-ON-CHANGE
          signal CAN4_ZR_SEAT_MLVent_Sta: start 26, 3 bit, big-endian, i-signal-type=PRIMITIVE, init-value=constant-reference=Init_CAN4_ZR_SEAT_MLVent_Sta, base-type=uint8, implementation-data-type=uint8, transfer-property=TRIGGERED-ON-CHANGE
          signal CAN4_ZR_SEAT_MRVent_Sta: start 18, 3 bit, big-endian, i-signal-type=PRIMITIVE, init-value=constant-reference=Init_CAN4_ZR_SEAT_MRVent_Sta, base-type=uint8, implementation-data-type=uint8, transfer-property=TRIGGERED-ON-CHANGE
          signal CAN4_ZR_SEAT_RVent_Sta: start 21, 3 bit, big-endian, i-signal-type=PRIMITIVE, init-value=constant-reference=Init_CAN4_ZR_SEAT_RVent_Sta, base-type=uint8, implementation-data-type=uint8, transfer-property=TRIGGERED-ON-CHANGE
      frame CAN4_zGW_APTC1: id 0x223, frame-length=24, can-addressing-mode=STANDARD, can-fd-frame-support=true, can-frame-rx-behavior=CAN-FD, can-frame-tx-behavior=CAN-FD
        pdu CAN4_zGW_APTC1: length=24, minimum-delay=0.0, transmission-mode-true-timing=cyclic-timing=time-period=0.1, unused-bit-pattern=0
          mapping CAN4_SG_zGW_APTC1: i-signal-group=CAN4_SG_zGW_APTC1, start-position=0, transfer-property=PENDING
          signal CAN4_FrntPTCBusLineHiV: start 177, 10 bit, big-endian, i-signal-type=PRIMITIVE, init-value=constant-reference=Init_CAN4_FrntPTCBusLineHiV, base-type=uint16, implementation-data-type=uint16, transfer-property=PENDING
          signal CAN4_FrntPTCComFlt: start 20, 1 bit, big-endian, i-signal-type=PRIMITIVE, init-value=constant-reference=Init_CAN4_FrntPTCComFlt, base-type=uint8, implementation-data-type=uint8, transfer-property=PENDING
          signal CAN4_FrntPTCFltSt: start 6, 2 bit, big-endian, i-signal-type=PRIMITIVE, init-value=constant-reference=Init_CAN4_FrntPTCFltSt, base-type=uint8, implementation-data-type=uint8, transfer-property=PENDING
          signal CAN4_FrntPTCHVOverUFlt: start 1, 1 bit, big-endian, i-signal-type=PRIMITIVE, init-value=constant-reference=Init_CAN4_FrntPTCHVOverUFlt, base-type=uint8, implementation-data-type=uint8, transfer-property=PENDING
          signal CAN4_FrntPTCHVUnderUFlt: start 2, 1 bit, big-endian, i-signal-type=PRIMITIVE, init-value=constant-reference=Init_CAN4_FrntPTCHVUnderUFlt, base-type=uint8, implementation-data-type=uint8, transfer-property=PENDING
          signal CAN4_FrntPTCHWVers: start 39, 8 bit, big-endian, i-signal-type=PRIMITIVE, init-value=constant-reference=Init_CAN4_FrntPTCHWVers, base-type=uint8, implementation-data-type=uint8, transfer-property=PENDING
          signal CAN4_FrntPTCLVOverUFlt: start 3, 1 bit, big-endian, i-signal-type=PRIMITIVE, init-value=constant-reference=Init_CAN4_FrntPTCLVOverUFlt, base-type=uint8, implementation-data-type=uint8, transfer-property=PENDING
          signal CAN4_FrntPTCLVUnderUFlt: start 4, 1 bit, big-endian, i-signal-type=PRIMITIVE, init-value=constant-reference=Init_CAN4_FrntPTCLVUnderUFlt, base-type=uint8, implementation-data-type=uint8, transfer-property=PENDING
          signal CAN4_FrntPTCLeActHeatPwr: start 87, 8 bit, big-endian, i-signal-type=PRIMITIVE, init-value=constant-reference=Init_CAN4_FrntPTCLeActHeatPwr, base-type=uint8, implementation-data-type=uint8, transfer-property=PENDING
          signal CAN4_FrntPTCLeBusLineC: start 167, 8 bit, big-endian, i-signal-type=PRIMITIVE, init-value=constant-reference=Init_CAN4_FrntPTCLeBusLineC, base-type=uint8, implementation-data-type=uint8, transfer-property=PENDING
          signal CAN4_FrntPTCLeCoreOverTFlt: start 12, 1 bit, big-endian, i-signal-type=PRIMITIVE, init-value=constant-reference=Init_CAN4_FrntPTCLeCoreOverTFlt, base-type=uint8, implementation-data-type=uint8, transfer-property=PENDING
          signal CAN4_FrntPTCLeCoreT: start 71, 8 bit, big-endian, i-signal-type=PRIMITIVE, init-value=constant-reference=Init_CAN4_FrntPTCLeCoreT, base-type=uint8, implementation-data-type=uint8, transfer-property=PENDING
          signal CAN4_FrntPTCLeCoreTSnsrFlt: start 14, 1 bit, big-endian, i-signal-type=PRIMITIVE, init-value=constant-reference=Init_CAN4_FrntPTCLeCoreTSnsrFlt, base-type=uint8, implementation-data-type=uint8, transfer-property=PENDING
          signal CAN4_FrntPTCLeIGBTOverTFlt: start 17, 1 bit, big-endian, i-signal-type=PRIMITIVE, init-value=constant-reference=Init_CAN4_FrntPTCLeIGBTOverTFlt, base-type=uint8, implementation-data-type=uint8, transfer-property=PENDING
          signal CAN4_FrntPTCLeIGBTShoCircFlt: start 10, 1 bit, big-endian, i-signal-type=PRIMITIVE, init-value=constant-reference=Init_CAN4_FrntPTCLeIGBTShoCircFlt, base-type=uint8, implementation-data-type=uint8, transfer-property=PENDING
          signal CAN4_FrntPTCLeIGBTT: start 103, 8 bit, big-endian, i-signal-type=PRIMITIVE, init-value=constant-reference=Init_CAN4_FrntPTCLeIGBTT, base-type=uint8, implementation-data-type=uint8, transfer-property=PENDING
          signal CAN4_FrntPTCLeIGBTTSnsrFlt: start 19, 1 bit, big-endian, i-signal-type=PRIMITIVE, init-value=constant-reference=Init_CAN4_FrntPTCLeIGBTTSnsrFlt, base-type=uint8, implementation-data-type=uint8, transfer-property=PENDING
          signal CAN4_FrntPTCLeOpentCircFlt: start 8, 1 bit, big-endian, i-signal-type=PRIMITIVE, init-value=constant-reference=Init_CAN4_FrntPTCLeOpentCircFlt, base-type=uint8, implementation-data-type=uint8, transfer-property=PENDING
          signal CAN4_FrntPTCLeOverAFlt: start 0, 1 bit, big-endian, i-signal-type=PRIMITIVE, init-value=constant-reference=Init_CAN4_FrntPTCLeOverAFlt, base-type=uint8, implementation-data-type=uint8, transfer-property=PENDING
          signal CAN4_FrntPTCPCBOverTFlt: start 21, 1 bit, big-endian, i-signal-type=PRIMITIVE, init-value=constant-reference=Init_CAN4_FrntPTCPCBOverTFlt, base-type=uint8, implementation-data-type=uint8, transfer-property=PENDING
          signal CAN4_FrntPTCPCBT: start 119, 8 bit, big-endian, i-signal-type=PRIMITIVE, init-value=constant-reference=Init_CAN4_FrntPTCPCBT, base-type=uint8, implementation-data-type=uint8, transfer-property=PENDING
          signal CAN4_FrntPTCPCBTSnsrFlt: start 22, 1 bit, big-endian, i-signal-type=PRIMITIVE, init-value=constant-reference=Init_CAN4_FrntPTCPCBTSnsrFlt, base-type=uint8, implementation-data-type=uint8, transfer-property=PENDING
          signal CAN4_FrntPTCRearLeActHeatPwr: start 135, 8 bit, big-endian, i-signal-type=PRIMITIVE, init-value=constant-reference=Init_CAN4_FrntPTCRearLeActHeatPwr, base-type=uint8, implementation-data-type=uint8, transfer-property=PENDING
          signal CAN4_FrntPTCRearLeBusLineC: start 63, 8 bit, big-endian, i-signal-type=PRIMITIVE, init-value=constant-reference=Init_CAN4_FrntPTCRearLeBusLineC, base-type=uint8, implementation-data-type=uint8, transfer-property=PENDING
          signal CAN4_FrntPTCRearLeCoreOverTFlt: start 40, 1 bit, big-endian, i-signal-type=PRIMITIVE, init-value=constant-reference=Init_CAN4_FrntPTCRearLeCoreOverTFlt, base-type=uint8, implementation-data-type=uint8, transfer-property=PENDING
          signal CAN4_FrntPTCRearLeCoreT: start 143, 8 bit, big-endian, i-signal-type=PRIMITIVE, init-value=constant-reference=Init_CAN4_FrntPTCRearLeCoreT, base-type=uint8, implementation-data-type=uint8, transfer-property=PENDING
          signal CAN4_FrntPTCRearLeCoreTSnsrFlt: start 54, 1 bit, big-endian, i-signal-type=PRIMITIVE, init-value=constant-reference=Init_CAN4_FrntPTCRearLeCoreTSnsrFlt, base-type=uint8, implementation-data-type=uint8, transfer-property=PENDING
          signal CAN4_FrntPTCRearLeIGBTShoCFlt: start 50, 1 bit, big-endian, i-signal-type=PRIMITIVE, init-value=constant-reference=Init_CAN4_FrntPTCRearLeIGBTShoCFlt, base-type=uint8, implementation-data-type=uint8, transfer-property=PENDING
          signal CAN4_FrntPTCRearLeOpentCircFlt: start 42, 1 bit, big-endian, i-signal-type=PRIMITIVE, init-value=constant-reference=Init_CAN4_FrntPTCRearLeOpentCircFlt, base-type=uint8, implementation-data-type=uint8, transfer-property=PENDING
          signal CAN4_FrntPTCRearLeOverAFlt: start 43, 1 bit, big-endian, i-signal-type=PRIMITIVE, init-value=constant-reference=Init_CAN4_FrntPTCRearLeOverAFlt, base-type=uint8, implementation-data-type=uint8, transfer-property=PENDING
          signal CAN4_FrntPTCRearRiActHeatPwr: start 151, 8 bit, big-endian, i-signal-type=PRIMITIVE, init-value=constant-reference=Init_CAN4_FrntPTCRearRiActHeatPwr, base-type=uint8, implementation-data-type=uint8, transfer-property=PENDING
          signal CAN4_FrntPTCRearRiBusLineC: start 127, 8 bit, big-endian, i-signal-type=PRIMITIVE, init-value=constant-reference=Init_CAN4_FrntPTCRearRiBusLineC, base-type=uint8, implementation-data-type=uint8, transfer-property=PENDING
          signal CAN4_FrntPTCRearRiCoreOverTFlt: start 41, 1 bit, big-endian, i-signal-type=PRIMITIVE, init-value=constant-reference=Init_CAN4_FrntPTCRearRiCoreOverTFlt, base-type=uint8, implementation-data-type=uint8, transfer-property=PENDING
          signal CAN4_FrntPTCRearRiCoreT: start 159, 8 bit, big-endian, i-signal-type=PRIMITIVE, init-value=constant-reference=Init_CAN4_FrntPTCRearRiCoreT, base-type=uint8, implementation-data-type=uint8, transfer-property=PENDING
          signal CAN4_FrntPTCRearRiCoreTSnsrFlt: start 55, 1 bit, big-endian, i-signal-type=PRIMITIVE, init-value=constant-reference=Init_CAN4_FrntPTCRearRiCoreTSnsrFlt, base-type=uint8, implementation-data-type=uint8, transfer-property=PENDING
          signal CAN4_FrntPTCRearRiIGBTShoCFlt: start 51, 1 bit, big-endian, i-signal-type=PRIMITIVE, init-value=constant-reference=Init_CAN4_FrntPTCRearRiIGBTShoCFlt, base-type=uint8, implementation-data-type=uint8, transfer-property=PENDING
          signal CAN4_FrntPTCRearRiOpentCircFlt: start 52, 1 bit, big-endian, i-signal-type=PRIMITIVE, init-value=constant-reference=Init_CAN4_FrntPTCRearRiOpentCircFlt, base-type=uint8, implementation-data-type=uint8, transfer-property=PENDING
          signal CAN4_FrntPTCRearRiOverAFlt: start 53, 1 bit, big-endian, i-signal-type=PRIMITIVE, init-value=constant-reference=Init_CAN4_FrntPTCRearRiOverAFlt, base-type=uint8, implementation-data-type=uint8, transfer-property=PENDING
          signal CAN4_FrntPTCRiActHeatPwr: start 95, 8 bit, big-endian, i-signal-type=PRIMITIVE, init-value=constant-reference=Init_CAN4_FrntPTCRiActHeatPwr, base-type=uint8, implementation-data-type=uint8, transfer-property=PENDING
          signal CAN4_FrntPTCRiBusLineC: start 175, 8 bit, big-endian, i-signal-type=PRIMITIVE, init-value=constant-reference=Init_CAN4_FrntPTCRiBusLineC, base-type=uint8, implementation-data-type=uint8, transfer-property=PENDING
          signal CAN4_FrntPTCRiCoreOverTFlt: start 11, 1 bit, big-endian, i-signal-type=PRIMITIVE, init-value=constant-reference=Init_CAN4_FrntPTCRiCoreOverTFlt, base-type=uint8, implementation-data-type=uint8, transfer-property=PENDING
          signal CAN4_FrntPTCRiCoreT: start 79, 8 bit, big-endian, i-signal-type=PRIMITIVE, init-value=constant-reference=Init_CAN4_FrntPTCRiCoreT, base-type=uint8, implementation-data-type=uint8, transfer-property=PENDING
          signal CAN4_FrntPTCRiCoreTSnsrFlt: start 13, 1 bit, big-endian, i-signal-type=PRIMITIVE, init-value=constant-reference=Init_CAN4_FrntPTCRiCoreTSnsrFlt, base-type=uint8, implementation-data-type=uint8, transfer-property=PENDING
          signal CAN4_FrntPTCRiIGBTOverTFlt: start 16, 1 bit, big-endian, i-signal-type=PRIMITIVE, init-value=constant-reference=Init_CAN4_FrntPTCRiIGBTOverTFlt, base-type=uint8, implementation-data-type=uint8, transfer-property=PENDING
          signal CAN4_FrntPTCRiIGBTShoCircFlt: start 9, 1 bit, big-endian, i-signal-type=PRIMITIVE, init-value=constant-reference=Init_CAN4_FrntPTCRiIGBTShoCircFlt, base-type=uint8, implementation-data-type=uint8, transfer-property=PENDING
          signal CAN4_FrntPTCRiIGBTT: start 111, 8 bit, big-endian, i-signal-type=PRIMITIVE, init-value=constant-reference=Init_CAN4_FrntPTCRiIGBTT, base-type=uint8, implementation-data-type=uint8, transfer-property=PENDING
          signal CAN4_FrntPTCRiIGBTTSnsrFlt: start 18, 1 bit, big-endian, i-signal-type=PRIMITIVE, init-value=constant-reference=Init_CAN4_FrntPTCRiIGBTTSnsrFlt, base-type=uint8, implementation-data-type=uint8, transfer-property=PENDING
          signal CAN4_FrntPTCRiOpentCircFlt: start 23, 1 bit, big-endian, i-signal-type=PRIMITIVE, init-value=constant-reference=Init_CAN4_FrntPTCRiOpentCircFlt, base-type=uint8, implementation-data-type=uint8, transfer-property=PENDING
          signal CAN4_FrntPTCRiOverAFlt: start 15, 1 bit, big-endian, i-signal-type=PRIMITIVE, init-value=constant-reference=Init_CAN4_FrntPTCRiOverAFlt, base-type=uint8, implementation-data-type=uint8, transfer-property=PENDING
          signal CAN4_FrntPTCSWVers: start 31, 8 bit, big-endian, i-signal-type=PRIMITIVE, init-value=constant-reference=Init_CAN4_FrntPTCSWVers, base-type=uint8, implementation-data-type=uint8, transfer-property=PENDING
          signal CAN4_FrntPTCSts: start 7, 1 bit, big-endian, i-signal-type=PRIMITIVE, init-value=constant-reference=Init_CAN4_FrntPTCSts, base-type=uint8, implementation-data-type=uint8, transfer-property=PENDING
          signal CAN4_FrntPTCSupplierCod: start 47, 4 bit, big-endian, i-signal-type=PRIMITIVE, init-value=constant-reference=Init_CAN4_FrntPTCSupplierCod, base-type=uint8, implementation-data-type=uint8, transfer-property=PENDING
      frame CAN4_zGW_CANFr1: id 0x30A, frame-length=32, can-addressing-mode=STANDARD, can-fd-frame-support=true, can-frame-rx-behavior=CAN-FD, can-frame-tx-behavior=CAN-FD
        pdu CAN4_zGW_CANFr1: length=32, minimum-delay=0.0, transmission-mode-true-timing=cyclic-timing=time-period=0.1, unused-bit-pattern=0
          mapping CAN4_SG_zGW_CANFr1: i-signal-group=CAN4_SG_zGW_CANFr1, start-position=0, transfer-property=PENDING
          signal CAN4_COMP_ActualPwr: start 228, 13 bit, big-endian, i-signal-type=PRIMITIVE, init-value=constant-reference=Init_CAN4_COMP_ActualPwr, base-type=uint16, implementation-data-type=uint16, transfer-property=PENDING
          signal CAN4_COMP_ComLost: start 58, 1 bit, big-endian, i-signal-type=PRIMITIVE, init-value=constant-reference=Init_CAN4_COMP_ComLost, base-type=uint8, implementation-data-type=uint8, transfer-property=PENDING
          signal CAN4_COMP_ConCur: start 103, 16 bit, big-endian, i-signal-type=PRIMITIVE, init-value=constant-reference=Init_CAN4_COMP_ConCur, base-type=uint16, implementation-data-type=uint16, transfer-property=PENDING
          signal CAN4_COMP_ConVolt: start 119, 16 bit, big-endian, i-signal-type=PRIMITIVE, init-value=constant-reference=Init_CAN4_COMP_ConVolt, base-type=uint16, implementation-data-type=uint16, transfer-property=PENDING
          signal CAN4_COMP_CtrlCircFlt: start 68, 1 bit, big-endian, i-signal-type=PRIMITIVE, init-value=constant-reference=Init_CAN4_COMP_CtrlCircFlt, base-type=uint8, implementation-data-type=uint8, transfer-property=PENDING
          signal CAN4_COMP_CurOverProtect: start 71, 1 bit, big-endian, i-signal-type=PRIMITIVE, init-value=constant-reference=Init_CAN4_COMP_CurOverProtect, base-type=uint8, implementation-data-type=uint8, transfer-property=PENDING
          signal CAN4_COMP_CurVaild: start 87, 1 bit, big-endian, i-signal-type=PRIMITIVE, init-value=constant-reference=Init_CAN4_COMP_CurVaild, base-type=uint8, implementation-data-type=uint8, transfer-property=PENDING
          signal CAN4_COMP_IPM_HWFLt: start 57, 1 bit, big-endian, i-signal-type=PRIMITIVE, init-value=constant-reference=Init_CAN4_COMP_IPM_HWFLt, base-type=uint8, implementation-data-type=uint8, transfer-property=PENDING
          signal CAN4_COMP_IPM_TempOverFlt: start 56, 1 bit, big-endian, i-signal-type=PRIMITIVE, init-value=constant-reference=Init_CAN4_COMP_IPM_TempOverFlt, base-type=uint8, implementation-data-type=uint8, transfer-property=PENDING
          signal CAN4_COMP_Init: start 65, 1 bit, big-endian, i-signal-type=PRIMITIVE, init-value=constant-reference=Init_CAN4_COMP_Init, base-type=uint8, implementation-data-type=uint8, transfer-property=PENDING
          signal CAN4_COMP_SpdVaild: start 64, 1 bit, big-endian, i-signal-type=PRIMITIVE, init-value=constant-reference=Init_CAN4_COMP_SpdVaild, base-type=uint8, implementation-data-type=uint8, transfer-property=PENDING
          signal CAN4_COMP_Sta: start 67, 2 bit, big-endian, i-signal-type=PRIMITIVE, init-value=constant-reference=Init_CAN4_COMP_Sta, base-type=uint8, implementation-data-type=uint8, transfer-property=PENDING
          signal CAN4_COMP_StatorSpd: start 85, 14 bit, big-endian, i-signal-type=PRIMITIVE, init-value=constant-reference=Init_CAN4_COMP_StatorSpd, base-type=uint16, implementation-data-type=uint16, transfer-property=PENDING
          signal CAN4_COMP_VoltLessErr: start 69, 1 bit, big-endian, i-signal-type=PRIMITIVE, init-value=constant-reference=Init_CAN4_COMP_VoltLessErr, base-type=uint8, implementation-data-type=uint8, transfer-property=PENDING
          signal CAN4_COMP_VoltOverErr: start 70, 1 bit, big-endian, i-signal-type=PRIMITIVE, init-value=constant-reference=Init_CAN4_COMP_VoltOverErr, base-type=uint8, implementation-data-type=uint8, transfer-property=PENDING
          signal CAN4_COMP_VoltVaild: start 86, 1 bit, big-endian, i-signal-type=PRIMITIVE, init-value=constant-reference=Init_CAN4_COMP_VoltVaild, base-type=uint8, implementation-data-type=uint8, transfer-property=PENDING
          signal CAN4_EAC_DrvVoltFalt: start 63, 1 bit, big-endian, i-signal-type=PRIMITIVE, init-value=constant-reference=Init_CAN4_EAC_DrvVoltFalt, base-type=uint8, implementation-data-type=uint8, transfer-property=PENDING
          signal CAN4_EAC_MotCrt: start 79, 8 bit, big-endian, i-signal-type=PRIMITIVE, init-value=constant-reference=Init_CAN4_EAC_MotCrt, base-type=uint8, implementation-data-type=uint8, transfer-property=PENDING
          signal CAN4_EAC_MotorLackFalt: start 62, 1 bit, big-endian, i-signal-type=PRIMITIVE, init-value=constant-reference=Init_CAN4_EAC_MotorLackFalt, base-type=uint8, implementation-data-type=uint8, transfer-property=PENDING
          signal CAN4_EAC_OvLoadFalt: start 61, 1 bit, big-endian, i-signal-type=PRIMITIVE, init-value=constant-reference=Init_CAN4_EAC_OvLoadFalt, base-type=uint8, implementation-data-type=uint8, transfer-property=PENDING
          signal CAN4_EAC_Temp: start 39, 8 bit, big-endian, i-signal-type=PRIMITIVE, init-value=constant-reference=Init_CAN4_EAC_Temp, base-type=uint8, implementation-data-type=uint8, transfer-property=PENDING
          signal CAN4_EAC_TempSnsrFalt: start 60, 1 bit, big-endian, i-signal-type=PRIMITIVE, init-value=constant-reference=Init_CAN4_EAC_TempSnsrFalt, base-type=uint8, implementation-data-type=uint8, transfer-property=PENDING
          signal CAN4_PTC1_PowerConsumption: start 31, 8 bit, big-endian, i-signal-type=PRIMITIVE, init-value=constant-reference=Init_CAN4_PTC1_PowerConsumption, base-type=uint8, implementation-data-type=uint8, transfer-property=PENDING
          signal CAN4_PTCActuCrntHSC6: start 161, 10 bit, big-endian, i-signal-type=PRIMITIVE, init-value=constant-reference=Init_CAN4_PTCActuCrntHSC6, base-type=uint16, implementation-data-type=uint16, transfer-property=PENDING
          signal CAN4_PTCActuPWMDutyHSC6: start 7, 8 bit, big-endian, i-signal-type=PRIMITIVE, init-value=constant-reference=Init_CAN4_PTCActuPWMDutyHSC6, base-type=uint8, implementation-data-type=uint8, transfer-property=PENDING
          signal CAN4_PTCActuPwrHSC6: start 47, 16 bit, big-endian, i-signal-type=PRIMITIVE, init-value=constant-reference=Init_CAN4_PTCActuPwrHSC6, base-type=uint16, implementation-data-type=uint16, transfer-property=PENDING
          signal CAN4_PTCActuVolHSC6: start 193, 10 bit, big-endian, i-signal-type=PRIMITIVE, init-value=constant-reference=Init_CAN4_PTCActuVolHSC6, base-type=uint16, implementation-data-type=uint16, transfer-property=PENDING
          signal CAN4_PTCChksmHSC6: start 183, 8 bit, big-endian, i-signal-type=PRIMITIVE, init-value=constant-reference=Init_CAN4_PTCChksmHSC6, base-type=uint8, implementation-data-type=uint8, transfer-property=PENDING
          signal CAN4_PTCFltLvlHSC6: start 199, 4 bit, big-endian, i-signal-type=PRIMITIVE, init-value=constant-reference=Init_CAN4_PTCFltLvlHSC6, base-type=uint8, implementation-data-type=uint8, transfer-property=PENDING
          signal CAN4_PTCHVLckStsHSC6: start 146, 1 bit, big-endian, i-signal-type=PRIMITIVE, init-value=constant-reference=Init_CAN4_PTCHVLckStsHSC6, base-type=uint8, implementation-data-type=uint8, transfer-property=PENDING
          signal CAN4_PTCIGBTOverHeatHSC6: start 145, 1 bit, big-endian, i-signal-type=PRIMITIVE, init-value=constant-reference=Init_CAN4_PTCIGBTOverHeatHSC6, base-type=uint8, implementation-data-type=uint8, transfer-property=PENDING
          signal CAN4_PTCIGBTStsHSC6: start 147, 1 bit, big-endian, i-signal-type=PRIMITIVE, init-value=constant-reference=Init_CAN4_PTCIGBTStsHSC6, base-type=uint8, implementation-data-type=uint8, transfer-property=PENDING
          signal CAN4_PTCIGBTTemHSC6: start 15, 9 bit, big-endian, i-signal-type=PRIMITIVE, init-value=constant-reference=Init_CAN4_PTCIGBTTemHSC6, base-type=uint16, implementation-data-type=uint16, transfer-property=PENDING
          signal CAN4_PTCNTCStsHSC6: start 164, 3 bit, big-endian, i-signal-type=PRIMITIVE, init-value=constant-reference=Init_CAN4_PTCNTCStsHSC6, base-type=uint8, implementation-data-type=uint8, transfer-property=PENDING
          signal CAN4_PTCOtptTemHSC6: start 128, 9 bit, big-endian, i-signal-type=PRIMITIVE, init-value=constant-reference=Init_CAN4_PTCOtptTemHSC6, base-type=uint16, implementation-data-type=uint16, transfer-property=PENDING
          signal CAN4_PTCOverCrntHSC6: start 130, 1 bit, big-endian, i-signal-type=PRIMITIVE, init-value=constant-reference=Init_CAN4_PTCOverCrntHSC6, base-type=uint8, implementation-data-type=uint8, transfer-property=PENDING
          signal CAN4_PTCOverHeatHSC6: start 129, 1 bit, big-endian, i-signal-type=PRIMITIVE, init-value=constant-reference=Init_CAN4_PTCOverHeatHSC6, base-type=uint8, implementation-data-type=uint8, transfer-property=PENDING
          signal CAN4_PTCOverVolHSC6: start 131, 1 bit, big-endian, i-signal-type=PRIMITIVE, init-value=constant-reference=Init_CAN4_PTCOverVolHSC6, base-type=uint8, implementation-data-type=uint8, transfer-property=PENDING
          signal CAN4_PTCPCBTemHSC6: start 144, 9 bit, big-endian, i-signal-type=PRIMITIVE, init-value=constant-reference=Init_CAN4_PTCPCBTemHSC6, base-type=uint16, implementation-data-type=uint16, transfer-property=PENDING
          signal CAN4_PTCRlngCtrHSC6: start 151, 4 bit, big-endian, i-signal-type=PRIMITIVE, init-value=constant-reference=Init_CAN4_PTCRlngCtrHSC6, base-type=uint8, implementation-data-type=uint8, transfer-property=PENDING
          signal CAN4_PTCSecChksmHSC6: start 191, 8 bit, big-endian, i-signal-type=PRIMITIVE, init-value=constant-reference=Init_CAN4_PTCSecChksmHSC6, base-type=uint8, implementation-data-type=uint8, transfer-property=PENDING
          signal CAN4_PTCSecRlngCtrHSC6: start 135, 4 bit, big-endian, i-signal-type=PRIMITIVE, init-value=constant-reference=Init_CAN4_PTCSecRlngCtrHSC6, base-type=uint8, implementation-data-type=uint8, transfer-property=PENDING
          signal CAN4_PTCStsHSC6: start 166, 2 bit, big-endian, i-signal-type=PRIMITIVE, init-value=constant-reference=Init_CAN4_PTCStsHSC6, base-type=uint8, implementation-data-type=uint8, transfer-property=PENDING
          signal CAN4_PTCUnderVolHSC6: start 167, 1 bit, big-endian, i-signal-type=PRIMITIVE, init-value=constant-reference=Init_CAN4_PTCUnderVolHSC6, base-type=uint8, implementation-data-type=uint8, transfer-property=PENDING
      frame CAN4_zGW_LINDr1: id 0x226, frame-length=32, can-addressing-mode=STANDARD, can-fd-frame-support=true, can-frame-rx-behavior=CAN-FD, can-frame-tx-behavior=CAN-FD
        pdu CAN4_zGW_LINDr1: length=32, minimum-delay=0.0, transmission-mode-true-timing={cyclic-timing=time-period=0.2, event-controlled-timing={number-of-repetitions=0, repetition-period=0}}, unused-bit-pattern=0
          mapping CAN4_SG_zGW_LINDr1: i-signal-group=CAN4_SG_zGW_LINDr1, start-position=0, transfer-property=TRIGGERED-ON-CHANGE
          signal CAN4_CSW_DimSw: start 251, 1 bit, big-endian, i-signal-type=PRIMITIVE, init-value=constant-reference=Init_CAN4_CSW_DimSw, base-type=uint8, implementation-data-type=uint8, transfer-property=TRIGGERED-ON-CHANGE
          signal CAN4_CSW_FWasSw_Sta: start 59, 2 bit, big-endian, i-signal-type=PRIMITIVE, init-value=constant-reference=Init_CAN4_CSW_FWasSw_Sta, base-type=uint8, implementation-data-type=uint8, transfer-property=TRIGGERED-ON-CHANGE
          signal CAN4_CSW_FWipSw_Sta: start 165, 3 bit, big-endian, i-signal-type=PRIMITIVE, init-value=constant-reference=Init_CAN4_CSW_FWipSw_Sta, base-type=uint8, implementation-data-type=uint8, transfer-property=TRIGGERED-ON-CHANGE
          signal CAN4_CSW_HW_version: start 71, 16 bit, big-endian, i-signal-type=PRIMITIVE, init-value=constant-reference=Init_CAN4_CSW_HW_version, base-type=uint16, implementation-data-type=uint16, transfer-property=PENDING
          signal CAN4_CSW_PassSW_Sta: start 252, 1 bit, big-endian, i-signal-type=PRIMITIVE, init-value=constant-reference=Init_CAN4_CSW_PassSW_Sta, base-type=uint8, implementation-data-type=uint8, transfer-property=TRIGGERED-ON-CHANGE
          signal CAN4_CSW_RWasSW_Sta: start 61, 2 bit, big-endian, i-signal-type=PRIMITIVE, init-value=constant-reference=Init_CAN4_CSW_RWasSW_Sta, base-type=uint8, implementation-data-type=uint8, transfer-property=TRIGGERED-ON-CHANGE
          signal CAN4_CSW_RWipIntSw_Sta: start 57, 2 bit, big-endian, i-signal-type=PRIMITIVE, init-value=constant-reference=Init_CAN4_CSW_RWipIntSw_Sta, base-type=uint8, implementation-data-type=uint8, transfer-property=TRIGGERED-ON-CHANGE
          signal CAN4_CSW_SW_version: start 87, 16 bit, big-endian, i-signal-type=PRIMITIVE, init-value=constant-reference=Init_CAN4_CSW_SW_version, base-type=uint16, implementation-data-type=uint16, transfer-property=PENDING
          signal CAN4_CSW_TurnSw_Sta: start 63, 2 bit, big-endian, i-signal-type=PRIMITIVE, init-value=constant-reference=Init_CAN4_CSW_TurnSw_Sta, base-type=uint8, implementation-data-type=uint8, transfer-property=TRIGGERED-ON-CHANGE
          signal CAN4_CSW_resp_error: start 253, 1 bit, big-endian, i-signal-type=PRIMITIVE, init-value=constant-reference=Init_CAN4_CSW_resp_error, base-type=uint8, implementation-data-type=uint8, transfer-property=TRIGGERED-ON-CHANGE
          signal CAN4_FAPWL_01_LIN_Response_Error: start 189, 1 bit, big-endian, i-signal-type=PRIMITIVE, init-value=constant-reference=Init_CAN4_FAPWL_01_LIN_Response_Error, base-type=uint8, implementation-data-type=uint8, transfer-property=TRIGGERED-ON-CHANGE
          signal CAN4_L_Drv_Motor_Relay_Error: start 184, 1 bit, big-endian, i-signal-type=PRIMITIVE, init-value=constant-reference=Init_CAN4_L_Drv_Motor_Relay_Error, base-type=uint8, implementation-data-type=uint8, transfer-property=TRIGGERED-ON-CHANGE
          signal CAN4_L_Drv_Motor_Ripple_Error: start 199, 1 bit, big-endian, i-signal-type=PRIMITIVE, init-value=constant-reference=Init_CAN4_L_Drv_Motor_Ripple_Error, base-type=uint8, implementation-data-type=uint8, transfer-property=TRIGGERED-ON-CHANGE
          signal CAN4_L_Drv_OverHeat_Protect: start 185, 1 bit, big-endian, i-signal-type=PRIMITIVE, init-value=constant-reference=Init_CAN4_L_Drv_OverHeat_Protect, base-type=uint8, implementation-data-type=uint8, transfer-property=TRIGGERED-ON-CHANGE
          signal CAN4_L_Drv_Val_Wdw_Opened: start 198, 7 bit, big-endian, i-signal-type=PRIMITIVE, init-value=constant-reference=Init_CAN4_L_Drv_Val_Wdw_Opened, base-type=uint8, implementation-data-type=uint8, transfer-property=PENDING
          signal CAN4_L_Drv_Wdw_Init: start 186, 1 bit, big-endian, i-signal-type=PRIMITIVE, init-value=constant-reference=Init_CAN4_L_Drv_Wdw_Init, base-type=uint8, implementation-data-type=uint8, transfer-property=TRIGGERED-ON-CHANGE
          signal CAN4_L_Drv_Wdw_LocalSwitch: start 205, 3 bit, big-endian, i-signal-type=PRIMITIVE, init-value=constant-reference=Init_CAN4_L_Drv_Wdw_LocalSwitch, base-type=uint8, implementation-data-type=uint8, transfer-property=TRIGGERED-ON-CHANGE
          signal CAN4_L_Drv_Wdw_OD_Sts: start 187, 1 bit, big-endian, i-signal-type=PRIMITIVE, init-value=constant-reference=Init_CAN4_L_Drv_Wdw_OD_Sts, base-type=uint8, implementation-data-type=uint8, transfer-property=TRIGGERED-ON-CHANGE
          signal CAN4_L_Drv_Wdw_Obs_InhibitSts: start 188, 1 bit, big-endian, i-signal-type=PRIMITIVE, init-value=constant-reference=Init_CAN4_L_Drv_Wdw_Obs_InhibitSts, base-type=uint8, implementation-data-type=uint8, transfer-property=TRIGGERED-ON-CHANGE
          signal CAN4_L_Drv_Wdw_Pas_Switch: start 162, 3 bit, big-endian, i-signal-type=PRIMITIVE, init-value=constant-reference=Init_CAN4_L_Drv_Wdw_Pas_Switch, base-type=uint8, implementation-data-type=uint8, transfer-property=TRIGGERED-ON-CHANGE
          signal CAN4_L_Drv_Wdw_PositionSts: start 207, 2 bit, big-endian, i-signal-type=PRIMITIVE, init-value=constant-reference=Init_CAN4_L_Drv_Wdw_PositionSts, base-type=uint8, implementation-data-type=uint8, transfer-property=TRIGGERED-ON-CHANGE
          signal CAN4_L_Drv_Wdw_RLD_Switch: start 154, 3 bit, big-endian, i-signal-type=PRIMITIVE, init-value=constant-reference=Init_CAN4_L_Drv_Wdw_RLD_Switch, base-type=uint8, implementation-data-type=uint8, transfer-property=TRIGGERED-ON-CHANGE
          signal CAN4_L_Drv_Wdw_RRD_Switch: start 157, 3 bit, big-endian, i-signal-type=PRIMITIVE, init-value=constant-reference=Init_CAN4_L_Drv_Wdw_RRD_Switch, base-type=uint8, implementation-data-type=uint8, transfer-property=TRIGGERED-ON-CHANGE
          signal CAN4_L_Drv_Wdw_Running_Sts: start 202, 3 bit, big-endian, i-signal-type=PRIMITIVE, init-value=constant-reference=Init_CAN4_L_Drv_Wdw_Running_Sts, base-type=uint8, implementation-data-type=uint8, transfer-property=TRIGGERED-ON-CHANGE
          signal CAN4_L_Pas_Motor_Relay_Error: start 54, 1 bit, big-endian, i-signal-type=PRIMITIVE, init-value=constant-reference=Init_CAN4_L_Pas_Motor_Relay_Error, base-type=uint8, implementation-data-type=uint8, transfer-property=TRIGGERED-ON-CHANGE
          signal CAN4_L_Pas_Motor_Ripple_Error: start 55, 1 bit, big-endian, i-signal-type=PRIMITIVE, init-value=constant-reference=Init_CAN4_L_Pas_Motor_Ripple_Error, base-type=uint8, implementation-data-type=uint8, transfer-property=TRIGGERED-ON-CHANGE
          signal CAN4_L_Pas_OverHeat_Protect: start 158, 1 bit, big-endian, i-signal-type=PRIMITIVE, init-value=constant-reference=Init_CAN4_L_Pas_OverHeat_Protect, base-type=uint8, implementation-data-type=uint8, transfer-property=TRIGGERED-ON-CHANGE
          signal CAN4_L_Pas_Val_Wdw_Opened: start 174, 7 bit, big-endian, i-signal-type=PRIMITIVE, init-value=constant-reference=Init_CAN4_L_Pas_Val_Wdw_Opened, base-type=uint8, implementation-data-type=uint8, transfer-property=PENDING
          signal CAN4_L_Pas_Wdw_Init: start 166, 1 bit, big-endian, i-signal-type=PRIMITIVE, init-value=constant-reference=Init_CAN4_L_Pas_Wdw_Init, base-type=uint8, implementation-data-type=uint8, transfer-property=TRIGGERED-ON-CHANGE
          signal CAN4_L_Pas_Wdw_LocalSwitch: start 181, 3 bit, big-endian, i-signal-type=PRIMITIVE, init-value=constant-reference=Init_CAN4_L_Pas_Wdw_LocalSwitch, base-type=uint8, implementation-data-type=uint8, transfer-property=TRIGGERED-ON-CHANGE
          signal CAN4_L_Pas_Wdw_OD_Sts: start 167, 1 bit, big-endian, i-signal-type=PRIMITIVE, init-value=constant-reference=Init_CAN4_L_Pas_Wdw_OD_Sts, base-type=uint8, implementation-data-type=uint8, transfer-property=TRIGGERED-ON-CHANGE
          signal CAN4_L_Pas_Wdw_Obs_InhibitSts: start 159, 1 bit, big-endian, i-signal-type=PRIMITIVE, init-value=constant-reference=Init_CAN4_L_Pas_Wdw_Obs_InhibitSts, base-type=uint8, implementation-data-type=uint8, transfer-property=TRIGGERED-ON-CHANGE
          signal CAN4_L_Pas_Wdw_PositionSts: start 183, 2 bit, big-endian, i-signal-type=PRIMITIVE, init-value=constant-reference=Init_CAN4_L_Pas_Wdw_PositionSts, base-type=uint8, implementation-data-type=uint8, transfer-property=TRIGGERED-ON-CHANGE
          signal CAN4_L_Pas_Wdw_Running_Sts: start 178, 3 bit, big-endian, i-signal-type=PRIMITIVE, init-value=constant-reference=Init_CAN4_L_Pas_Wdw_Running_Sts, base-type=uint8, implementation-data-type=uint8, transfer-property=TRIGGERED-ON-CHANGE
          signal CAN4_L_Power_Status: start 191, 2 bit, big-endian, i-signal-type=PRIMITIVE, init-value=constant-reference=Init_CAN4_L_Power_Status, base-type=uint8, implementation-data-type=uint8, transfer-property=TRIGGERED-ON-CHANGE
          signal CAN4_L_RLD_Motor_Relay_Error: start 246, 1 bit, big-endian, i-signal-type=PRIMITIVE, init-value=constant-reference=Init_CAN4_L_RLD_Motor_Relay_Error, base-type=uint8, implementation-data-type=uint8, transfer-property=TRIGGERED-ON-CHANGE
          signal CAN4_L_RLD_Motor_Ripple_Error: start 245, 1 bit, big-endian, i-signal-type=PRIMITIVE, init-value=constant-reference=Init_CAN4_L_RLD_Motor_Ripple_Error, base-type=uint8, implementation-data-type=uint8, transfer-property=TRIGGERED-ON-CHANGE
          signal CAN4_L_RLD_OverHeat_Protect: start 247, 1 bit, big-endian, i-signal-type=PRIMITIVE, init-value=constant-reference=Init_CAN4_L_RLD_OverHeat_Protect, base-type=uint8, implementation-data-type=uint8, transfer-property=TRIGGERED-ON-CHANGE
          signal CAN4_L_RLD_Val_Wdw_Opened: start 238, 7 bit, big-endian, i-signal-type=PRIMITIVE, init-value=constant-reference=Init_CAN4_L_RLD_Val_Wdw_Opened, base-type=uint8, implementation-data-type=uint8, transfer-property=PENDING
          signal CAN4_L_RLD_Wdw_Init: start 215, 1 bit, big-endian, i-signal-type=PRIMITIVE, init-value=constant-reference=Init_CAN4_L_RLD_Wdw_Init, base-type=uint8, implementation-data-type=uint8, transfer-property=TRIGGERED-ON-CHANGE
          signal CAN4_L_RLD_Wdw_LocalSwitch: start 242, 3 bit, big-endian, i-signal-type=PRIMITIVE, init-value=constant-reference=Init_CAN4_L_RLD_Wdw_LocalSwitch, base-type=uint8, implementation-data-type=uint8, transfer-property=TRIGGERED-ON-CHANGE
          signal CAN4_L_RLD_Wdw_OD_Sts: start 239, 1 bit, big-endian, i-signal-type=PRIMITIVE, init-value=constant-reference=Init_CAN4_L_RLD_Wdw_OD_Sts, base-type=uint8, implementation-data-type=uint8, transfer-property=TRIGGERED-ON-CHANGE
          signal CAN4_L_RLD_Wdw_Obs_InhibitSts: start 224, 1 bit, big-endian, i-signal-type=PRIMITIVE, init-value=constant-reference=Init_CAN4_L_RLD_Wdw_Obs_InhibitSts, base-type=uint8, implementation-data-type=uint8, transfer-property=TRIGGERED-ON-CHANGE
          signal CAN4_L_RLD_Wdw_PositionSts: start 244, 2 bit, big-endian, i-signal-type=PRIMITIVE, init-value=constant-reference=Init_CAN4_L_RLD_Wdw_PositionSts, base-type=uint8, implementation-data-type=uint8, transfer-property=TRIGGERED-ON-CHANGE
          signal CAN4_L_RLD_Wdw_Running_Sts: start 250, 3 bit, big-endian, i-signal-type=PRIMITIVE, init-value=constant-reference=Init_CAN4_L_RLD_Wdw_Running_Sts, base-type=uint8, implementation-data-type=uint8, transfer-property=TRIGGERED-ON-CHANGE
          signal CAN4_L_RRD_Motor_Relay_Error: start 217, 1 bit, big-endian, i-signal-type=PRIMITIVE, init-value=constant-reference=Init_CAN4_L_RRD_Motor_Relay_Error, base-type=uint8, implementation-data-type=uint8, transfer-property=TRIGGERED-ON-CHANGE
          signal CAN4_L_RRD_Motor_Ripple_Error: start 216, 1 bit, big-endian, i-signal-type=PRIMITIVE, init-value=constant-reference=Init_CAN4_L_RRD_Motor_Ripple_Error, base-type=uint8, implementation-data-type=uint8, transfer-property=TRIGGERED-ON-CHANGE
          signal CAN4_L_RRD_OverHeat_Protect: start 218, 1 bit, big-endian, i-signal-type=PRIMITIVE, init-value=constant-reference=Init_CAN4_L_RRD_OverHeat_Protect, base-type=uint8, implementation-data-type=uint8, transfer-property=TRIGGERED-ON-CHANGE
          signal CAN4_L_RRD_Val_Wdw_Opened: start 214, 7 bit, big-endian, i-signal-type=PRIMITIVE, init-value=constant-reference=Init_CAN4_L_RRD_Val_Wdw_Opened, base-type=uint8, implementation-data-type=uint8, transfer-property=PENDING
          signal CAN4_L_RRD_Wdw_Init: start 219, 1 bit, big-endian, i-signal-type=PRIMITIVE, init-value=constant-reference=Init_CAN4_L_RRD_Wdw_Init, base-type=uint8, implementation-data-type=uint8, transfer-property=TRIGGERED-ON-CHANGE
          signal CAN4_L_RRD_Wdw_LocalSwitch: start 231, 3 bit, big-endian, i-signal-type=PRIMITIVE, init-value=constant-reference=Init_CAN4_L_RRD_Wdw_LocalSwitch, base-type=uint8, implementation-data-type=uint8, transfer-property=TRIGGERED-ON-CHANGE
          signal CAN4_L_RRD_Wdw_OD_Sts: start 220, 1 bit, big-endian, i-signal-type=PRIMITIVE, init-value=constant-reference=Init_CAN4_L_RRD_Wdw_OD_Sts, base-type=uint8, implementation-data-type=uint8, transfer-property=TRIGGERED-ON-CHANGE
          signal CAN4_L_RRD_Wdw_Obs_InhibitSts: start 221, 1 bit, big-endian, i-signal-type=PRIMITIVE, init-value=constant-reference=Init_CAN4_L_RRD_Wdw_Obs_InhibitSts, base-type=uint8, implementation-data-type=uint8, transfer-property=TRIGGERED-ON-CHANGE
          signal CAN4_L_RRD_Wdw_PositionSts: start 223, 2 bit, big-endian, i-signal-type=PRIMITIVE, init-value=constant-reference=Init_CAN4_L_RRD_Wdw_PositionSts, base-type=uint8, implementation-data-type=uint8, transfer-property=TRIGGERED-ON-CHANGE
          signal CAN4_L_RRD_Wdw_Running_Sts: start 228, 3 bit, big-endian, i-signal-type=PRIMITIVE, init-value=constant-reference=Init_CAN4_L_RRD_Wdw_Running_Sts, base-type=uint8, implementation-data-type=uint8, transfer-property=TRIGGERED-ON-CHANGE
          signal CAN4_RAPWL_01_LIN_Response_Error: start 225, 1 bit, big-endian, i-signal-type=PRIMITIVE, init-value=constant-reference=Init_CAN4_RAPWL_01_LIN_Response_Error, base-type=uint8, implementation-data-type=uint8, transfer-property=TRIGGERED-ON-CHANGE
          signal CAN4_RLS_LIN_Resp_Err: start 175, 1 bit, big-endian, i-signal-type=PRIMITIVE, init-value=constant-reference=Init_CAN4_RLS_LIN_Resp_Err, base-type=uint8, implementation-data-type=uint8, transfer-property=TRIGGERED-ON-CHANGE
          signal CAN4_RLS_Lamp_Sta: start 147, 1 bit, big-endian, i-signal-type=PRIMITIVE, init-value=constant-reference=Init_CAN4_RLS_Lamp_Sta, base-type=uint8, implementation-data-type=uint8, transfer-property=TRIGGERED-ON-CHANGE
          signal CAN4_RLS_LightSnrErr: start 255, 1 bit, big-endian, i-signal-type=PRIMITIVE, init-value=constant-reference=Init_CAN4_RLS_LightSnrErr, base-type=uint8, implementation-data-type=uint8, transfer-property=TRIGGERED-ON-CHANGE
          signal CAN4_RLS_RainSnrErr: start 254, 1 bit, big-endian, i-signal-type=PRIMITIVE, init-value=constant-reference=Init_CAN4_RLS_RainSnrErr, base-type=uint8, implementation-data-type=uint8, transfer-property=TRIGGERED-ON-CHANGE
          signal CAN4_RLS_RainSnrWiperCmd: start 146, 3 bit, big-endian, i-signal-type=PRIMITIVE, init-value=constant-reference=Init_CAN4_RLS_RainSnrWiperCmd, base-type=uint8, implementation-data-type=uint8, transfer-property=TRIGGERED-ON-CHANGE
          signal CAN4_SWC2_HW_Version: start 7, 16 bit, big-endian, i-signal-type=PRIMITIVE, init-value=constant-reference=Init_CAN4_SWC2_HW_Version, base-type=uint16, implementation-data-type=uint16, transfer-property=PENDING
          signal CAN4_SWC2_L_ADAS_Sta: start 41, 1 bit, big-endian, i-signal-type=PRIMITIVE, init-value=constant-reference=Init_CAN4_SWC2_L_ADAS_Sta, base-type=uint8, implementation-data-type=uint8, transfer-property=TRIGGERED-ON-CHANGE
          signal CAN4_SWC2_L_DriveMode_Sta: start 51, 1 bit, big-endian, i-signal-type=PRIMITIVE, init-value=constant-reference=Init_CAN4_SWC2_L_DriveMode_Sta, base-type=uint8, implementation-data-type=uint8, transfer-property=TRIGGERED-ON-CHANGE
          signal CAN4_SWC2_L_Home_Sta: start 40, 1 bit, big-endian, i-signal-type=PRIMITIVE, init-value=constant-reference=Init_CAN4_SWC2_L_Home_Sta, base-type=uint8, implementation-data-type=uint8, transfer-property=TRIGGERED-ON-CHANGE
          signal CAN4_SWC2_L_Left_Sta: start 47, 1 bit, big-endian, i-signal-type=PRIMITIVE, init-value=constant-reference=Init_CAN4_SWC2_L_Left_Sta, base-type=uint8, implementation-data-type=uint8, transfer-property=TRIGGERED-ON-CHANGE
          signal CAN4_SWC2_L_RegenUp_Sta: start 42, 1 bit, big-endian, i-signal-type=PRIMITIVE, init-value=constant-reference=Init_CAN4_SWC2_L_RegenUp_Sta, base-type=uint8, implementation-data-type=uint8, transfer-property=TRIGGERED-ON-CHANGE
          signal CAN4_SWC2_L_Right_Sta: start 43, 1 bit, big-endian, i-signal-type=PRIMITIVE, init-value=constant-reference=Init_CAN4_SWC2_L_Right_Sta, base-type=uint8, implementation-data-type=uint8, transfer-property=TRIGGERED-ON-CHANGE
          signal CAN4_SWC2_L_ScrollDown_Sta: start 44, 1 bit, big-endian, i-signal-type=PRIMITIVE, init-value=constant-reference=Init_CAN4_SWC2_L_ScrollDown_Sta, base-type=uint8, implementation-data-type=uint8, transfer-property=TRIGGERED-ON-CHANGE
          signal CAN4_SWC2_L_ScrollPress_Sta: start 45, 1 bit, big-endian, i-signal-type=PRIMITIVE, init-value=constant-reference=Init_CAN4_SWC2_L_ScrollPress_Sta, base-type=uint8, implementation-data-type=uint8, transfer-property=TRIGGERED-ON-CHANGE
          signal CAN4_SWC2_L_ScrollUp_Sta: start 46, 1 bit, big-endian, i-signal-type=PRIMITIVE, init-value=constant-reference=Init_CAN4_SWC2_L_ScrollUp_Sta, base-type=uint8, implementation-data-type=uint8, transfer-property=TRIGGERED-ON-CHANGE
          signal CAN4_SWC2_R_Customize_Sta: start 32, 1 bit, big-endian, i-signal-type=PRIMITIVE, init-value=constant-reference=Init_CAN4_SWC2_R_Customize_Sta, base-type=uint8, implementation-data-type=uint8, transfer-property=TRIGGERED-ON-CHANGE
          signal CAN4_SWC2_R_Left_Sta: start 35, 1 bit, big-endian, i-signal-type=PRIMITIVE, init-value=constant-reference=Init_CAN4_SWC2_R_Left_Sta, base-type=uint8, implementation-data-type=uint8, transfer-property=TRIGGERED-ON-CHANGE
          signal CAN4_SWC2_R_PageSwitch_Sta: start 33, 1 bit, big-endian, i-signal-type=PRIMITIVE, init-value=constant-reference=Init_CAN4_SWC2_R_PageSwitch_Sta, base-type=uint8, implementation-data-type=uint8, transfer-property=TRIGGERED-ON-CHANGE
          signal CAN4_SWC2_R_RegenDown_Sta: start 52, 1 bit, big-endian, i-signal-type=PRIMITIVE, init-value=constant-reference=Init_CAN4_SWC2_R_RegenDown_Sta, base-type=uint8, implementation-data-type=uint8, transfer-property=TRIGGERED-ON-CHANGE
          signal CAN4_SWC2_R_Right_Sta: start 39, 1 bit, big-endian, i-signal-type=PRIMITIVE, init-value=constant-reference=Init_CAN4_SWC2_R_Right_Sta, base-type=uint8, implementation-data-type=uint8, transfer-property=TRIGGERED-ON-CHANGE
          signal CAN4_SWC2_R_ScrollDown_Sta: start 36, 1 bit, big-endian, i-signal-type=PRIMITIVE, init-value=constant-reference=Init_CAN4_SWC2_R_ScrollDown_Sta, base-type=uint8, implementation-data-type=uint8, transfer-property=TRIGGERED-ON-CHANGE
          signal CAN4_SWC2_R_ScrollPress_Sta: start 37, 1 bit, big-endian, i-signal-type=PRIMITIVE, init-value=constant-reference=Init_CAN4_SWC2_R_ScrollPress_Sta, base-type=uint8, implementation-data-type=uint8, transfer-property=TRIGGERED-ON-CHANGE
          signal CAN4_SWC2_R_ScrollUp_Sta: start 38, 1 bit, big-endian, i-signal-type=PRIMITIVE, init-value=constant-reference=Init_CAN4_SWC2_R_ScrollUp_Sta, base-type=uint8, implementation-data-type=uint8, transfer-property=TRIGGERED-ON-CHANGE
          signal CAN4_SWC2_R_VR_Sta: start 34, 1 bit, big-endian, i-signal-type=PRIMITIVE, init-value=constant-reference=Init_CAN4_SWC2_R_VR_Sta, base-type=uint8, implementation-data-type=uint8, transfer-property=TRIGGERED-ON-CHANGE
          signal CAN4_SWC2_ResponseError: start 53, 1 bit, big-endian, i-signal-type=PRIMITIVE, init-value=constant-reference=Init_CAN4_SWC2_ResponseError, base-type=uint8, implementation-data-type=uint8, transfer-property=TRIGGERED-ON-CHANGE
          signal CAN4_SWC2_SW_Version: start 23, 16 bit, big-endian, i-signal-type=PRIMITIVE, init-value=constant-reference=Init_CAN4_SWC2_SW_Version, base-type=uint16, implementation-data-type=uint16, transfer-property=PENDING
          signal CAN4_SWC_ACC_Sta: start 132, 1 bit, big-endian, i-signal-type=PRIMITIVE, init-value=constant-reference=Init_CAN4_SWC_ACC_Sta, base-type=uint8, implementation-data-type=uint8, transfer-property=TRIGGERED-ON-CHANGE
          signal CAN4_SWC_A_HW_version: start 119, 16 bit, big-endian, i-signal-type=PRIMITIVE, init-value=constant-reference=Init_CAN4_SWC_A_HW_version, base-type=uint16, implementation-data-type=uint16, transfer-property=PENDING
          signal CAN4_SWC_A_Resp_Err: start 131, 1 bit, big-endian, i-signal-type=PRIMITIVE, init-value=constant-reference=Init_CAN4_SWC_A_Resp_Err, base-type=uint8, implementation-data-type=uint8, transfer-property=TRIGGERED-ON-CHANGE
          signal CAN4_SWC_A_SW_version: start 103, 16 bit, big-endian, i-signal-type=PRIMITIVE, init-value=constant-reference=Init_CAN4_SWC_A_SW_version, base-type=uint16, implementation-data-type=uint16, transfer-property=PENDING
          signal CAN4_SWC_CANCEL_Sta: start 133, 1 bit, big-endian, i-signal-type=PRIMITIVE, init-value=constant-reference=Init_CAN4_SWC_CANCEL_Sta, base-type=uint8, implementation-data-type=uint8, transfer-property=TRIGGERED-ON-CHANGE
          signal CAN4_SWC_Distance_Sta: start 130, 1 bit, big-endian, i-signal-type=PRIMITIVE, init-value=constant-reference=Init_CAN4_SWC_Distance_Sta, base-type=uint8, implementation-data-type=uint8, transfer-property=TRIGGERED-ON-CHANGE
          signal CAN4_SWC_Down_Sta: start 129, 1 bit, big-endian, i-signal-type=PRIMITIVE, init-value=constant-reference=Init_CAN4_SWC_Down_Sta, base-type=uint8, implementation-data-type=uint8, transfer-property=TRIGGERED-ON-CHANGE
          signal CAN4_SWC_Drivemode_Sta: start 135, 2 bit, big-endian, i-signal-type=PRIMITIVE, init-value=constant-reference=Init_CAN4_SWC_Drivemode_Sta, base-type=uint8, implementation-data-type=uint8, transfer-property=TRIGGERED-ON-CHANGE
          signal CAN4_SWC_LKA_Sta: start 148, 1 bit, big-endian, i-signal-type=PRIMITIVE, init-value=constant-reference=Init_CAN4_SWC_LKA_Sta, base-type=uint8, implementation-data-type=uint8, transfer-property=TRIGGERED-ON-CHANGE
          signal CAN4_SWC_Left_Sta: start 143, 1 bit, big-endian, i-signal-type=PRIMITIVE, init-value=constant-reference=Init_CAN4_SWC_Left_Sta, base-type=uint8, implementation-data-type=uint8, transfer-property=TRIGGERED-ON-CHANGE
          signal CAN4_SWC_RegenDown: start 139, 1 bit, big-endian, i-signal-type=PRIMITIVE, init-value=constant-reference=Init_CAN4_SWC_RegenDown, base-type=uint8, implementation-data-type=uint8, transfer-property=TRIGGERED-ON-CHANGE
          signal CAN4_SWC_RegenUp: start 128, 1 bit, big-endian, i-signal-type=PRIMITIVE, init-value=constant-reference=Init_CAN4_SWC_RegenUp, base-type=uint8, implementation-data-type=uint8, transfer-property=TRIGGERED-ON-CHANGE
          signal CAN4_SWC_Res_Up_Sta: start 140, 1 bit, big-endian, i-signal-type=PRIMITIVE, init-value=constant-reference=Init_CAN4_SWC_Res_Up_Sta, base-type=uint8, implementation-data-type=uint8, transfer-property=TRIGGERED-ON-CHANGE
          signal CAN4_SWC_Right_Sta: start 138, 1 bit, big-endian, i-signal-type=PRIMITIVE, init-value=constant-reference=Init_CAN4_SWC_Right_Sta, base-type=uint8, implementation-data-type=uint8, transfer-property=TRIGGERED-ON-CHANGE
          signal CAN4_SWC_Set_down_Sta: start 137, 1 bit, big-endian, i-signal-type=PRIMITIVE, init-value=constant-reference=Init_CAN4_SWC_Set_down_Sta, base-type=uint8, implementation-data-type=uint8, transfer-property=TRIGGERED-ON-CHANGE
          signal CAN4_SWC_Trip_Sta: start 136, 1 bit, big-endian, i-signal-type=PRIMITIVE, init-value=constant-reference=Init_CAN4_SWC_Trip_Sta, base-type=uint8, implementation-data-type=uint8, transfer-property=TRIGGERED-ON-CHANGE
          signal CAN4_SWC_Undefined_Sta: start 149, 1 bit, big-endian, i-signal-type=PRIMITIVE, init-value=constant-reference=Init_CAN4_SWC_Undefined_Sta, base-type=uint8, implementation-data-type=uint8, transfer-property=TRIGGERED-ON-CHANGE
          signal CAN4_SWC_Up_Sta: start 151, 1 bit, big-endian, i-signal-type=PRIMITIVE, init-value=constant-reference=Init_CAN4_SWC_Up_Sta, base-type=uint8, implementation-data-type=uint8, transfer-property=TRIGGERED-ON-CHANGE
          signal CAN4_SWC_VR_Sta: start 150, 1 bit, big-endian, i-signal-type=PRIMITIVE, init-value=constant-reference=Init_CAN4_SWC_VR_Sta, base-type=uint8, implementation-data-type=uint8, transfer-property=TRIGGERED-ON-CHANGE
          signal CAN4_SWC_mode_Sta: start 142, 1 bit, big-endian, i-signal-type=PRIMITIVE, init-value=constant-reference=Init_CAN4_SWC_mode_Sta, base-type=uint8, implementation-data-type=uint8, transfer-property=TRIGGERED-ON-CHANGE
          signal CAN4_SWC_resp_error: start 141, 1 bit, big-endian, i-signal-type=PRIMITIVE, init-value=constant-reference=Init_CAN4_SWC_resp_error, base-type=uint8, implementation-data-type=uint8, transfer-property=TRIGGERED-ON-CHANGE
      frame CAN4_zGW_LINFr1: id 0x228, frame-length=32, can-addressing-mode=STANDARD, can-fd-frame-support=true, can-frame-rx-behavior=CAN-FD, can-frame-tx-behavior=CAN-FD
        pdu CAN4_zGW_LINFr1: length=32, minimum-delay=0.0, transmission-mode-true-timing=cyclic-timing=time-period=0.1, unused-bit-pattern=0
          mapping CAN4_SG_zGW_LINFr1: i-signal-group=CAN4_SG_zGW_LINFr1, start-position=0, transfer-property=PENDING
          signal CAN4_AGS_Actual_Position: start 7, 8 bit, big-endian, i-signal-type=PRIMITIVE, init-value=constant-reference=Init_CAN4_AGS_Actual_Position, base-type=uint8, implementation-data-type=uint8, transfer-property=PENDING
          signal CAN4_AGS_Actuator_Blocked: start 9, 1 bit, big-endian, i-signal-type=PRIMITIVE, init-value=constant-reference=Init_CAN4_AGS_Actuator_Blocked, base-type=uint8, implementation-data-type=uint8, transfer-property=PENDING
          signal CAN4_AGS_Actuator_Fault: start 8, 1 bit, big-endian, i-signal-type=PRIMITIVE, init-value=constant-reference=Init_CAN4_AGS_Actuator_Fault, base-type=uint8, implementation-data-type=uint8, transfer-property=PENDING
          signal CAN4_AGS_Calibration_Active: start 10, 1 bit, big-endian, i-signal-type=PRIMITIVE, init-value=constant-reference=Init_CAN4_AGS_Calibration_Active, base-type=uint8, implementation-data-type=uint8, transfer-property=PENDING
          signal CAN4_AGS_Calibration_Indicated: start 11, 1 bit, big-endian, i-signal-type=PRIMITIVE, init-value=constant-reference=Init_CAN4_AGS_Calibration_Indicated, base-type=uint8, implementation-data-type=uint8, transfer-property=PENDING
          signal CAN4_AGS_Electrical_Error: start 12, 1 bit, big-endian, i-signal-type=PRIMITIVE, init-value=constant-reference=Init_CAN4_AGS_Electrical_Error, base-type=uint8, implementation-data-type=uint8, transfer-property=PENDING
          signal CAN4_AGS_LINResponse_Error: start 23, 1 bit, big-endian, i-signal-type=PRIMITIVE, init-value=constant-reference=Init_CAN4_AGS_LINResponse_Error, base-type=uint8, implementation-data-type=uint8, transfer-property=PENDING
          signal CAN4_AGS_Low_Voltage_Error: start 15, 1 bit, big-endian, i-signal-type=PRIMITIVE, init-value=constant-reference=Init_CAN4_AGS_Low_Voltage_Error, base-type=uint8, implementation-data-type=uint8, transfer-property=PENDING
          signal CAN4_AGS_Sensor_Error: start 13, 1 bit, big-endian, i-signal-type=PRIMITIVE, init-value=constant-reference=Init_CAN4_AGS_Sensor_Error, base-type=uint8, implementation-data-type=uint8, transfer-property=PENDING
          signal CAN4_AGS_Temperature_Error: start 14, 1 bit, big-endian, i-signal-type=PRIMITIVE, init-value=constant-reference=Init_CAN4_AGS_Temperature_Error, base-type=uint8, implementation-data-type=uint8, transfer-property=PENDING
          signal CAN4_FGS_BatteryErr_Sta: start 85, 2 bit, big-endian, i-signal-type=PRIMITIVE, init-value=constant-reference=Init_CAN4_FGS_BatteryErr_Sta, base-type=uint8, implementation-data-type=uint8, transfer-property=PENDING
          signal CAN4_FGS_BlowerErr_Sta: start 143, 2 bit, big-endian, i-signal-type=PRIMITIVE, init-value=constant-reference=Init_CAN4_FGS_BlowerErr_Sta, base-type=uint8, implementation-data-type=uint8, transfer-property=PENDING
          signal CAN4_FGS_Channel1TypeRsp_Sta: start 135, 8 bit, big-endian, i-signal-type=PRIMITIVE, init-value=constant-reference=Init_CAN4_FGS_Channel1TypeRsp_Sta, base-type=uint8, implementation-data-type=uint8, transfer-property=PENDING
          signal CAN4_FGS_Channel2TypeRsp_Sta: start 127, 8 bit, big-endian, i-signal-type=PRIMITIVE, init-value=constant-reference=Init_CAN4_FGS_Channel2TypeRsp_Sta, base-type=uint8, implementation-data-type=uint8, transfer-property=PENDING
          signal CAN4_FGS_Channel3TypeRsp_Sta: start 119, 8 bit, big-endian, i-signal-type=PRIMITIVE, init-value=constant-reference=Init_CAN4_FGS_Channel3TypeRsp_Sta, base-type=uint8, implementation-data-type=uint8, transfer-property=PENDING
          signal CAN4_FGS_HW_Version_Sta: start 159, 4 bit, big-endian, i-signal-type=PRIMITIVE, init-value=constant-reference=Init_CAN4_FGS_HW_Version_Sta, base-type=uint8, implementation-data-type=uint8, transfer-property=PENDING
          signal CAN4_FGS_IntenRsp_Sta: start 141, 2 bit, big-endian, i-signal-type=PRIMITIVE, init-value=constant-reference=Init_CAN4_FGS_IntenRsp_Sta, base-type=uint8, implementation-data-type=uint8, transfer-property=PENDING
          signal CAN4_FGS_LINResponseErr_Sta: start 167, 1 bit, big-endian, i-signal-type=PRIMITIVE, init-value=constant-reference=Init_CAN4_FGS_LINResponseErr_Sta, base-type=uint8, implementation-data-type=uint8, transfer-property=PENDING
          signal CAN4_FGS_LifeHole1_Sta: start 111, 8 bit, big-endian, i-signal-type=PRIMITIVE, init-value=constant-reference=Init_CAN4_FGS_LifeHole1_Sta, base-type=uint8, implementation-data-type=uint8, transfer-property=PENDING
          signal CAN4_FGS_LifeHole2_Sta: start 103, 8 bit, big-endian, i-signal-type=PRIMITIVE, init-value=constant-reference=Init_CAN4_FGS_LifeHole2_Sta, base-type=uint8, implementation-data-type=uint8, transfer-property=PENDING
          signal CAN4_FGS_LifeHole3_Sta: start 95, 8 bit, big-endian, i-signal-type=PRIMITIVE, init-value=constant-reference=Init_CAN4_FGS_LifeHole3_Sta, base-type=uint8, implementation-data-type=uint8, transfer-property=PENDING
          signal CAN4_FGS_MotorErr_Sta: start 139, 2 bit, big-endian, i-signal-type=PRIMITIVE, init-value=constant-reference=Init_CAN4_FGS_MotorErr_Sta, base-type=uint8, implementation-data-type=uint8, transfer-property=PENDING
          signal CAN4_FGS_MotorInit_Sta: start 137, 2 bit, big-endian, i-signal-type=PRIMITIVE, init-value=constant-reference=Init_CAN4_FGS_MotorInit_Sta, base-type=uint8, implementation-data-type=uint8, transfer-property=PENDING
          signal CAN4_FGS_SW_Version_Sta: start 155, 4 bit, big-endian, i-signal-type=PRIMITIVE, init-value=constant-reference=Init_CAN4_FGS_SW_Version_Sta, base-type=uint8, implementation-data-type=uint8, transfer-property=PENDING
          signal CAN4_FGS_StsRsp_Sta: start 86, 1 bit, big-endian, i-signal-type=PRIMITIVE, init-value=constant-reference=Init_CAN4_FGS_StsRsp_Sta, base-type=uint8, implementation-data-type=uint8, transfer-property=PENDING
          signal CAN4_FGS_TypRsp_Sta: start 145, 2 bit, big-endian, i-signal-type=PRIMITIVE, init-value=constant-reference=Init_CAN4_FGS_TypRsp_Sta, base-type=uint8, implementation-data-type=uint8, transfer-property=PENDING
          signal CAN4_FGS_TypeUnknow1_Sta: start 151, 2 bit, big-endian, i-signal-type=PRIMITIVE, init-value=constant-reference=Init_CAN4_FGS_TypeUnknow1_Sta, base-type=uint8, implementation-data-type=uint8, transfer-property=PENDING
          signal CAN4_FGS_TypeUnknow2_Sta: start 149, 2 bit, big-endian, i-signal-type=PRIMITIVE, init-value=constant-reference=Init_CAN4_FGS_TypeUnknow2_Sta, base-type=uint8, implementation-data-type=uint8, transfer-property=PENDING
          signal CAN4_FGS_TypeUnknow3_Sta: start 147, 2 bit, big-endian, i-signal-type=PRIMITIVE, init-value=constant-reference=Init_CAN4_FGS_TypeUnknow3_Sta, base-type=uint8, implementation-data-type=uint8, transfer-property=PENDING
          signal CAN4_ION_IONErr_Sta: start 81, 2 bit, big-endian, i-signal-type=PRIMITIVE, init-value=constant-reference=Init_CAN4_ION_IONErr_Sta, base-type=uint8, implementation-data-type=uint8, transfer-property=PENDING
          signal CAN4_ION_IONRespErr_Sta: start 83, 1 bit, big-endian, i-signal-type=PRIMITIVE, init-value=constant-reference=Init_CAN4_ION_IONRespErr_Sta, base-type=uint8, implementation-data-type=uint8, transfer-property=PENDING
          signal CAN4_ION_ION_Sta: start 82, 1 bit, big-endian, i-signal-type=PRIMITIVE, init-value=constant-reference=Init_CAN4_ION_ION_Sta, base-type=uint8, implementation-data-type=uint8, transfer-property=PENDING
      frame CAN4_zGW_SEAT1: id 0x356, frame-length=16, can-addressing-mode=STANDARD, can-fd-frame-support=true, can-frame-rx-behavior=CAN-FD, can-frame-tx-behavior=CAN-FD
        pdu CAN4_zGW_SEAT1: length=16, minimum-delay=0.0, transmission-mode-true-timing={cyclic-timing=time-period=0.2, event-controlled-timing={number-of-repetitions=0, repetition-period=0}}, unused-bit-pattern=0
          mapping CAN4_SG_zGW_SEAT1: i-signal-group=CAN4_SG_zGW_SEAT1, start-position=0, transfer-property=TRIGGERED-ON-CHANGE
          signal CAN4_DSEAT_AntiAct_Sta: start 33, 1 bit, big-endian, i-signal-type=PRIMITIVE, init-value=constant-reference=Init_CAN4_DSEAT_AntiAct_Sta, base-type=uint8, implementation-data-type=uint8, transfer-property=TRIGGERED-ON-CHANGE
          signal CAN4_DSEAT_Anti_Sta: start 32, 1 bit, big-endian, i-signal-type=PRIMITIVE, init-value=constant-reference=Init_CAN4_DSEAT_Anti_Sta, base-type=uint8, implementation-data-type=uint8, transfer-property=TRIGGERED-ON-CHANGE
          signal CAN4_DSEAT_EntryAct_Sta: start 41, 1 bit, big-endian, i-signal-type=PRIMITIVE, init-value=constant-reference=Init_CAN4_DSEAT_EntryAct_Sta, base-type=uint8, implementation-data-type=uint8, transfer-property=TRIGGERED-ON-CHANGE
          signal CAN4_DSEAT_EntryFun_Sta: start 40, 1 bit, big-endian, i-signal-type=PRIMITIVE, init-value=constant-reference=Init_CAN4_DSEAT_EntryFun_Sta, base-type=uint8, implementation-data-type=uint8, transfer-property=TRIGGERED-ON-CHANGE
          signal CAN4_DSEAT_Error_Sta: start 48, 1 bit, big-endian, i-signal-type=PRIMITIVE, init-value=constant-reference=Init_CAN4_DSEAT_Error_Sta, base-type=uint8, implementation-data-type=uint8, transfer-property=TRIGGERED-ON-CHANGE
          signal CAN4_DSEAT_FL_Pos: start 7, 8 bit, big-endian, i-signal-type=PRIMITIVE, init-value=constant-reference=Init_CAN4_DSEAT_FL_Pos, base-type=uint8, implementation-data-type=uint8, transfer-property=PENDING
          signal CAN4_DSEAT_HW_Ver: start 71, 16 bit, big-endian, i-signal-type=PRIMITIVE, init-value=constant-reference=Init_CAN4_DSEAT_HW_Ver, base-type=uint16, implementation-data-type=uint16, transfer-property=PENDING
          signal CAN4_DSEAT_Mode: start 39, 3 bit, big-endian, i-signal-type=PRIMITIVE, init-value=constant-reference=Init_CAN4_DSEAT_Mode, base-type=uint8, implementation-data-type=uint8, transfer-property=TRIGGERED-ON-CHANGE
          signal CAN4_DSEAT_RL_Pos: start 23, 8 bit, big-endian, i-signal-type=PRIMITIVE, init-value=constant-reference=Init_CAN4_DSEAT_RL_Pos, base-type=uint8, implementation-data-type=uint8, transfer-property=PENDING
          signal CAN4_DSEAT_Rec_Pos: start 31, 8 bit, big-endian, i-signal-type=PRIMITIVE, init-value=constant-reference=Init_CAN4_DSEAT_Rec_Pos, base-type=uint8, implementation-data-type=uint8, transfer-property=PENDING
          signal CAN4_DSEAT_SW_Ver: start 87, 16 bit, big-endian, i-signal-type=PRIMITIVE, init-value=constant-reference=Init_CAN4_DSEAT_SW_Ver, base-type=uint16, implementation-data-type=uint16, transfer-property=PENDING
          signal CAN4_DSEAT_Slid_Pos: start 15, 8 bit, big-endian, i-signal-type=PRIMITIVE, init-value=constant-reference=Init_CAN4_DSEAT_Slid_Pos, base-type=uint8, implementation-data-type=uint8, transfer-property=PENDING
          signal CAN4_DSEAT_Vent_Sta: start 36, 3 bit, big-endian, i-signal-type=PRIMITIVE, init-value=constant-reference=Init_CAN4_DSEAT_Vent_Sta, base-type=uint8, implementation-data-type=uint8, transfer-property=TRIGGERED-ON-CHANGE
          signal CAN4_DSEAT_heater_sta: start 44, 3 bit, big-endian, i-signal-type=PRIMITIVE, init-value=constant-reference=Init_CAN4_DSEAT_heater_sta, base-type=uint8, implementation-data-type=uint8, transfer-property=TRIGGERED-ON-CHANGE
          signal CAN4_PSEAT_Error_Sta: start 49, 1 bit, big-endian, i-signal-type=PRIMITIVE, init-value=constant-reference=Init_CAN4_PSEAT_Error_Sta, base-type=uint8, implementation-data-type=uint8, transfer-property=TRIGGERED-ON-CHANGE
          signal CAN4_PSEAT_HW_Ver: start 103, 16 bit, big-endian, i-signal-type=PRIMITIVE, init-value=constant-reference=Init_CAN4_PSEAT_HW_Ver, base-type=uint16, implementation-data-type=uint16, transfer-property=PENDING
          signal CAN4_PSEAT_Mode: start 55, 3 bit, big-endian, i-signal-type=PRIMITIVE, init-value=constant-reference=Init_CAN4_PSEAT_Mode, base-type=uint8, implementation-data-type=uint8, transfer-property=TRIGGERED-ON-CHANGE
          signal CAN4_PSEAT_SW_Ver: start 119, 16 bit, big-endian, i-signal-type=PRIMITIVE, init-value=constant-reference=Init_CAN4_PSEAT_SW_Ver, base-type=uint16, implementation-data-type=uint16, transfer-property=PENDING
          signal CAN4_PSEAT_Vent_Sta: start 52, 3 bit, big-endian, i-signal-type=PRIMITIVE, init-value=constant-reference=Init_CAN4_PSEAT_Vent_Sta, base-type=uint8, implementation-data-type=uint8, transfer-property=TRIGGERED-ON-CHANGE
          signal CAN4_PSEAT_heater_sta: start 47, 3 bit, big-endian, i-signal-type=PRIMITIVE, init-value=constant-reference=Init_CAN4_PSEAT_heater_sta, base-type=uint8, implementation-data-type=uint8, transfer-property=TRIGGERED-ON-CHANGE
      frame CAN4_NMm_FUSION_TX: id 0x500, frame-length=8, can-addressing-mode=STANDARD, can-fd-frame-support=false, can-frame-rx-behavior=CAN-20, can-frame-tx-behavior=CAN-20
        nm pdu CAN4_NMm_FUSION_TX: length=8, unused-bit-pattern=0
      frame CAN4_NMm_FUSION_RX: id 0x500, frame-length=8, can-addressing-mode=STANDARD, can-fd-frame-support=false, can-frame-rx-behavior=CAN-20, can-frame-tx-behavior=CAN-20
        nm pdu CAN4_NMm_FUSION_RX: length=8, unused-bit-pattern=0
